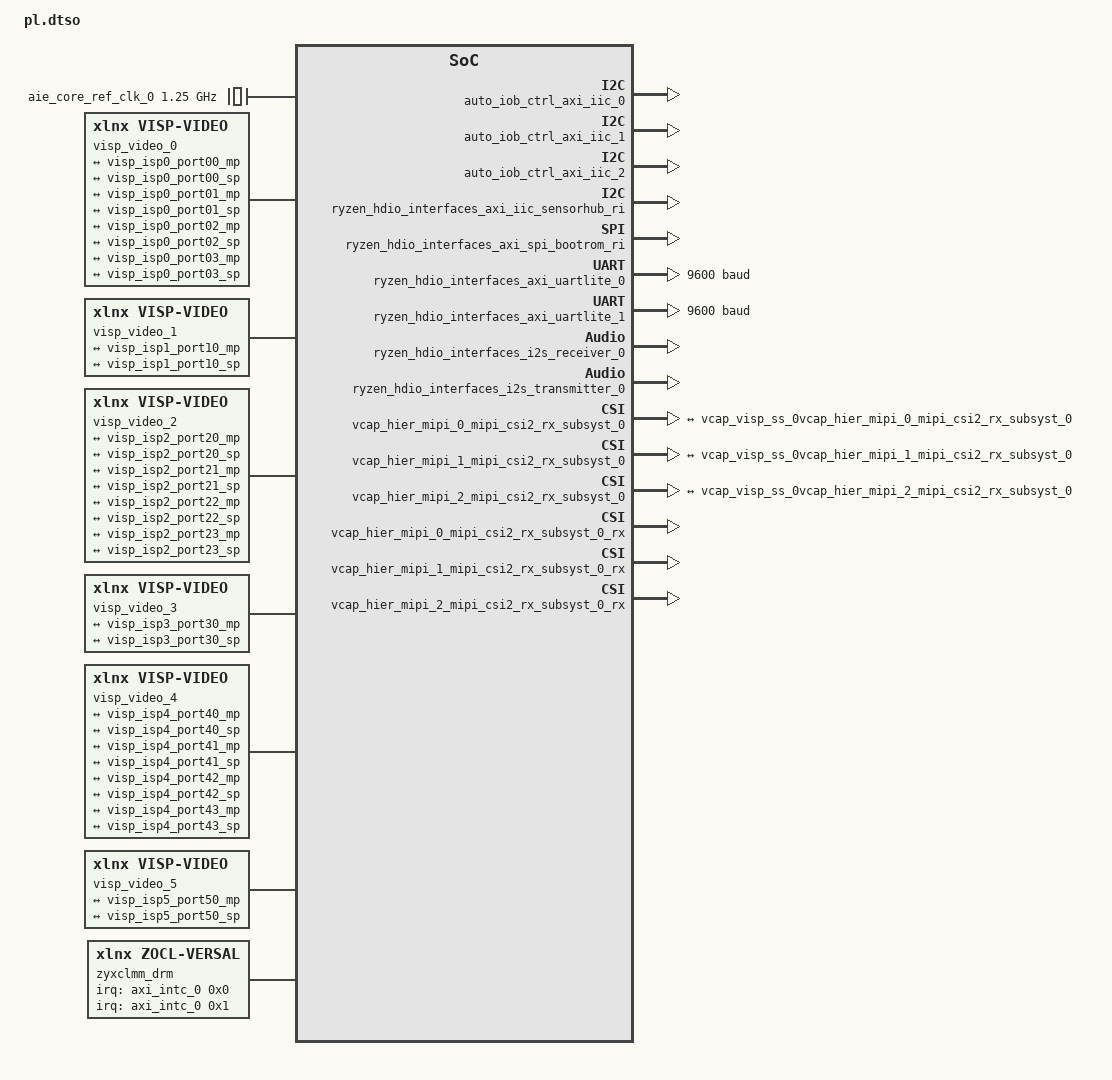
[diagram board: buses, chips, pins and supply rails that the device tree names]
/dts-v1/;
/plugin/;

&fpga {
        firmware-name = "vpl_gen_fixed_pld.pdi";

        misc_clk_2: misc_clk_2 {
                #clock-cells = <0x0>;
                clock-frequency = <0x8f0cba9>;
                compatible = "fixed-clock";
        };

        misc_clk_3: misc_clk_3 {
                #clock-cells = <0x0>;
                clock-frequency = <0x5f5e100>;
                compatible = "fixed-clock";
        };

        misc_clk_1: misc_clk_1 {
                #clock-cells = <0x0>;
                clock-frequency = <0xbebba30>;
                compatible = "fixed-clock";
        };

        misc_clk_5: misc_clk_5 {
                #clock-cells = <0x0>;
                clock-frequency = <0x7735940>;
                compatible = "fixed-clock";
        };

        misc_clk_0: misc_clk_0 {
                #clock-cells = <0x0>;
                clock-frequency = <0x5f5dd18>;
                compatible = "fixed-clock";
        };

        misc_clk_4: misc_clk_4 {
                #clock-cells = <0x0>;
                clock-frequency = <0x7f27c21>;
                compatible = "fixed-clock";
        };
};

&amba {

        axi_intc_0: interrupt-controller@b01b0000 {
                xlnx,name = "axi_intc_0";
                xlnx,async-intr = <0xffcfffff>;
                interrupt-names = "irq";
                interrupt-controller;
                xlnx,ivar-rst-val = <0x10>;
                xlnx,has-fast = <0x0>;
                clock-names = "s_axi_aclk";
                xlnx,is-fast = <0x0>;
                xlnx,processor-clk-freq-mhz = <0x64>;
                xlnx,cascade-master = <0x0>;
                xlnx,sense-of-irq-level-type = "Active_High";
                xlnx,intc-type = <0x0>;
                xlnx,has-ipr = <0x1>;
                xlnx,mb-clk-not-connected = <0x1>;
                xlnx,edk-iptype = "PERIPHERAL";
                xlnx,num-sync-ff = <0x2>;
                xlnx,has-cie = <0x1>;
                xlnx,enable-async = <0x0>;
                xlnx,has-sie = <0x1>;
                xlnx,num-intr-inputs = <0x20>;
                xlnx,irq-connection = <0x1>;
                xlnx,num-sw-intr = <0x0>;
                xlnx,s-axi-aclk-freq-mhz = <0x5f5dd18>;
                clocks = <&misc_clk_0>;
                xlnx,addr-width = <0x20>;
                reg = <0x0 0xb01b0000 0x0 0x10000>;
                xlnx,has-ilr = <0x0>;
                xlnx,ip-name = "axi_intc";
                xlnx,en-cascade-mode = <0x0>;
                interrupt-parent = <&gic>;
                xlnx,irq-active = <0x1>;
                xlnx,ivar-reset-value = <0x10>;
                xlnx,kind-of-lvl = <0xffffffff>;
                xlnx,disable-synchronizers = <0x0>;
                compatible = "xlnx,axi-intc-4.1", "xlnx,xps-intc-1.00.a";
                xlnx,has-ivr = <0x1>;
                xlnx,irq-is-level = <0x1>;
                xlnx,kind-of-edge = <0xffffffff>;
                xlnx,kind-of-intr = <0xffe38>;
                xlnx,edk-special = "INTR_CTRL";
                xlnx,sense-of-irq-edge-type = "Rising";
                interrupts = <0x0 0x8f 0x4>;
                #interrupt-cells = <0x2>;
        };

        ai_engine_0: ai_engine@20000000000 {
                xlnx,aie-site = "AIE2PS";
                xlnx,name = "ai_engine_0";
                xlnx,start-column = <0x0>;
                xlnx,name-si-axi = "S00_AXI";
                xlnx,shim-rows = /bits/ 8 <0x00 0x01>;
                xlnx,core-rows = /bits/ 8 <0x02 0x04>;
                xlnx,num-trig-out = <0x0>;
                xlnx,en-ext-rst = <0x1>;
                xlnx,num-trig-in = <0x0>;
                power-domains = <&versal2_firmware 0x18800000>;
                clock-names = "aclk0";
                xlnx,selected-nsu = <0x0>;
                xlnx,edk-iptype = "PERIPHERAL";
                xlnx,fast-dm-write;
                xlnx,clk-names = "aclk0";
                xlnx,aie-core-ref-ctrl-freqmhz = <0x4e2>;
                xlnx,num-column = <0x1>;
                xlnx,name-mi-axi = "M00_AXI";
                xlnx,num-si-axis = <0x0>;
                #address-cells = <0x2>;
                xlnx,partition-enabled = <0x0>;
                xlnx,num-clks = <0x0>;
                ranges;
                xlnx,num-noc-axis-clks = <0x0>;
                clocks = <&aie_core_ref_clk_0>;
                reg = <0x200 0x0 0x1 0x0>;
                xlnx,fast-pm-write;
                xlnx,num-si-axi = <0x1>;
                #size-cells = <0x2>;
                xlnx,ip-name = "ai_engine";
                xlnx,mi-destid-pins;
                xlnx,mem-rows = /bits/ 8 <0x01 0x01>;
                xlnx,aie-gen = [05];
                xlnx,en-addr-virtualization = <0x0>;
                xlnx,aie-max-freq = <0x4e2>;
                xlnx,num-mi-axis = <0x0>;
                xlnx,aie-ref-clk-freqmhz = <0x1fc9f08>;
                compatible = "xlnx,ai-engine-2.0", "xlnx,ai-engine-v2.0";
                xlnx,num-mi-axi = <0x18>;

                aie_aperture_0: aie_aperture@20000000000 {
                        xlnx,columns = <0x0 0x18>;
                        reg = <0x200 0x0 0x1 0x0>;
                        interrupt-names = "interrupt1", "interrupt2", "interrupt3";
                        #size-cells = <0x2>;
                        xlnx,node-id = <0x18800000>;
                        power-domains = <&versal2_firmware 0x18800000>;
                        #address-cells = <0x2>;
                        interrupts = <0x0 0xce 0x4 0x0 0xcf 0x4 0x0 0xd0 0x4>;
                        interrupt-parent = <&gic>;
                        xlnx,device-name = <0x0>;
                };
        };

        auto_iob_ctrl_axi_gpio_0: gpio@b0130000 {
                xlnx,all-inputs = <0x0>;
                xlnx,name = "auto_iob_ctrl_axi_gpio_0";
                xlnx,tri-default = <0xf00>;
                clock-names = "s_axi_aclk";
                xlnx,gpio2-width = <0x20>;
                xlnx,dout-default-2 = <0x0>;
                xlnx,edk-iptype = "PERIPHERAL";
                xlnx,gpio2-board-interface = "Custom";
                xlnx,interrupt-present = <0x0>;
                device_type = "gpio";
                gpio-controller;
                xlnx,all-outputs-2 = <0x0>;
                clocks = <&misc_clk_0>;
                xlnx,all-inputs-2 = <0x0>;
                reg = <0x0 0xb0130000 0x0 0x10000>;
                xlnx,tri-default-2 = <0xffffffff>;
                xlnx,ip-name = "axi_gpio";
                xlnx,is-dual = <0x0>;
                xlnx,dout-default = <0x24042>;
                xlnx,gpio-width = <0x18>;
                #gpio-cells = <0x2>;
                xlnx,all-outputs = <0x0>;
                compatible = "xlnx,axi-gpio-2.0", "xlnx,xps-gpio-1.00.a";
                xlnx,gpio-board-interface = "Custom";
        };

        auto_iob_ctrl_axi_gpio_1: gpio@b0140000 {
                xlnx,all-inputs = <0x0>;
                xlnx,name = "auto_iob_ctrl_axi_gpio_1";
                xlnx,tri-default = <0xffffffff>;
                clock-names = "s_axi_aclk";
                xlnx,gpio2-width = <0x20>;
                xlnx,dout-default-2 = <0x0>;
                xlnx,edk-iptype = "PERIPHERAL";
                xlnx,gpio2-board-interface = "Custom";
                xlnx,interrupt-present = <0x0>;
                device_type = "gpio";
                gpio-controller;
                xlnx,all-outputs-2 = <0x0>;
                clocks = <&misc_clk_0>;
                xlnx,all-inputs-2 = <0x0>;
                reg = <0x0 0xb0140000 0x0 0x10000>;
                xlnx,tri-default-2 = <0xffffffff>;
                xlnx,ip-name = "axi_gpio";
                xlnx,is-dual = <0x0>;
                xlnx,dout-default = <0x0>;
                xlnx,gpio-width = <0x5>;
                #gpio-cells = <0x2>;
                xlnx,all-outputs = <0x0>;
                compatible = "xlnx,axi-gpio-2.0", "xlnx,xps-gpio-1.00.a";
                xlnx,gpio-board-interface = "Custom";
        };

        auto_iob_ctrl_axi_gpio_2: gpio@b0150000 {
                xlnx,all-inputs = <0x0>;
                xlnx,name = "auto_iob_ctrl_axi_gpio_2";
                xlnx,tri-default = <0xffffffff>;
                clock-names = "s_axi_aclk";
                xlnx,gpio2-width = <0x20>;
                xlnx,dout-default-2 = <0x0>;
                xlnx,edk-iptype = "PERIPHERAL";
                xlnx,gpio2-board-interface = "Custom";
                xlnx,interrupt-present = <0x0>;
                device_type = "gpio";
                gpio-controller;
                xlnx,all-outputs-2 = <0x0>;
                clocks = <&misc_clk_0>;
                xlnx,all-inputs-2 = <0x0>;
                reg = <0x0 0xb0150000 0x0 0x10000>;
                xlnx,tri-default-2 = <0xffffffff>;
                xlnx,ip-name = "axi_gpio";
                xlnx,is-dual = <0x0>;
                xlnx,dout-default = <0x0>;
                xlnx,gpio-width = <0x5>;
                #gpio-cells = <0x2>;
                xlnx,all-outputs = <0x0>;
                compatible = "xlnx,axi-gpio-2.0", "xlnx,xps-gpio-1.00.a";
                xlnx,gpio-board-interface = "Custom";
        };

        auto_iob_ctrl_axi_gpio_3: gpio@b0160000 {
                xlnx,all-inputs = <0x0>;
                xlnx,name = "auto_iob_ctrl_axi_gpio_3";
                xlnx,tri-default = <0xffffffff>;
                clock-names = "s_axi_aclk";
                xlnx,gpio2-width = <0x20>;
                xlnx,dout-default-2 = <0x0>;
                xlnx,edk-iptype = "PERIPHERAL";
                xlnx,gpio2-board-interface = "Custom";
                xlnx,interrupt-present = <0x0>;
                device_type = "gpio";
                gpio-controller;
                xlnx,all-outputs-2 = <0x0>;
                clocks = <&misc_clk_0>;
                xlnx,all-inputs-2 = <0x0>;
                reg = <0x0 0xb0160000 0x0 0x10000>;
                xlnx,tri-default-2 = <0xffffffff>;
                xlnx,ip-name = "axi_gpio";
                xlnx,is-dual = <0x0>;
                xlnx,dout-default = <0x0>;
                xlnx,gpio-width = <0x6>;
                #gpio-cells = <0x2>;
                xlnx,all-outputs = <0x0>;
                compatible = "xlnx,axi-gpio-2.0", "xlnx,xps-gpio-1.00.a";
                xlnx,gpio-board-interface = "Custom";
        };

        auto_iob_ctrl_axi_iic_0: i2c@80000000 {
                xlnx,sda-inertial-delay = <0x0>;
                xlnx,axi-aclk-freq-mhz = <0x5f5dd18>;
                xlnx,name = "auto_iob_ctrl_axi_iic_0";
                xlnx,smbus-pmbus-host = <0x0>;
                xlnx,iic-freq = <0x186a0>;
                xlnx,timing-reg-width = <0x20>;
                xlnx,iic-board-interface = "Custom";
                interrupt-names = "iic2intc_irpt";
                xlnx,default-value = <0x0>;
                xlnx,ten-bit-adr = <0x0>;
                clock-names = "s_axi_aclk";
                xlnx,sda-level = <0x1>;
                xlnx,static-timing-reg-width = <0x0>;
                xlnx,edk-iptype = "PERIPHERAL";
                xlnx,s-axi-aclk-freq-hz = <0x5f5dd18>;
                xlnx,gpo-width = <0x1>;
                clocks = <&misc_clk_0>;
                reg = <0x0 0x80000000 0x0 0x10000>;
                xlnx,disable-setup-violation-check = <0x0>;
                xlnx,ip-name = "axi_iic";
                interrupt-parent = <&gic>;
                xlnx,scl-inertial-delay = <0x0>;
                compatible = "xlnx,axi-iic-2.1", "xlnx,xps-iic-2.00.a";
                xlnx,iic-freq-khz = <0x64>;
                interrupts = <0x0 0x5a 0x4>;
        };

        auto_iob_ctrl_axi_iic_1: i2c@80010000 {
                xlnx,sda-inertial-delay = <0x0>;
                xlnx,axi-aclk-freq-mhz = <0x5f5dd18>;
                xlnx,name = "auto_iob_ctrl_axi_iic_1";
                xlnx,smbus-pmbus-host = <0x0>;
                xlnx,iic-freq = <0x186a0>;
                xlnx,timing-reg-width = <0x20>;
                xlnx,iic-board-interface = "Custom";
                interrupt-names = "iic2intc_irpt";
                xlnx,default-value = <0x0>;
                xlnx,ten-bit-adr = <0x0>;
                clock-names = "s_axi_aclk";
                xlnx,sda-level = <0x1>;
                xlnx,static-timing-reg-width = <0x0>;
                xlnx,edk-iptype = "PERIPHERAL";
                xlnx,s-axi-aclk-freq-hz = <0x5f5dd18>;
                xlnx,gpo-width = <0x1>;
                clocks = <&misc_clk_0>;
                reg = <0x0 0x80010000 0x0 0x10000>;
                xlnx,disable-setup-violation-check = <0x0>;
                xlnx,ip-name = "axi_iic";
                interrupt-parent = <&gic>;
                xlnx,scl-inertial-delay = <0x0>;
                compatible = "xlnx,axi-iic-2.1", "xlnx,xps-iic-2.00.a";
                xlnx,iic-freq-khz = <0x64>;
                interrupts = <0x0 0x58 0x4>;
        };

        auto_iob_ctrl_axi_iic_2: i2c@80020000 {
                xlnx,sda-inertial-delay = <0x0>;
                xlnx,axi-aclk-freq-mhz = <0x5f5dd18>;
                xlnx,name = "auto_iob_ctrl_axi_iic_2";
                xlnx,smbus-pmbus-host = <0x0>;
                xlnx,iic-freq = <0x186a0>;
                xlnx,timing-reg-width = <0x20>;
                xlnx,iic-board-interface = "Custom";
                interrupt-names = "iic2intc_irpt";
                xlnx,default-value = <0x0>;
                xlnx,ten-bit-adr = <0x0>;
                clock-names = "s_axi_aclk";
                xlnx,sda-level = <0x1>;
                xlnx,static-timing-reg-width = <0x0>;
                xlnx,edk-iptype = "PERIPHERAL";
                xlnx,s-axi-aclk-freq-hz = <0x5f5dd18>;
                xlnx,gpo-width = <0x1>;
                clocks = <&misc_clk_0>;
                reg = <0x0 0x80020000 0x0 0x10000>;
                xlnx,disable-setup-violation-check = <0x0>;
                xlnx,ip-name = "axi_iic";
                interrupt-parent = <&gic>;
                xlnx,scl-inertial-delay = <0x0>;
                compatible = "xlnx,axi-iic-2.1", "xlnx,xps-iic-2.00.a";
                xlnx,iic-freq-khz = <0x64>;
                interrupts = <0x0 0x59 0x4>;
        };

        axi_gpio_rst: gpio@b01a0000 {
                xlnx,all-inputs = <0x0>;
                xlnx,name = "axi_gpio_rst";
                xlnx,tri-default = <0xffffffff>;
                clock-names = "s_axi_aclk";
                xlnx,gpio2-width = <0x20>;
                xlnx,dout-default-2 = <0x0>;
                xlnx,edk-iptype = "PERIPHERAL";
                xlnx,gpio2-board-interface = "Custom";
                xlnx,interrupt-present = <0x0>;
                device_type = "gpio";
                gpio-controller;
                xlnx,all-outputs-2 = <0x0>;
                clocks = <&misc_clk_0>;
                xlnx,all-inputs-2 = <0x0>;
                reg = <0x0 0xb01a0000 0x0 0x10000>;
                xlnx,tri-default-2 = <0xffffffff>;
                xlnx,ip-name = "axi_gpio";
                xlnx,is-dual = <0x0>;
                xlnx,dout-default = <0xffffffff>;
                xlnx,gpio-width = <0x20>;
                #gpio-cells = <0x2>;
                xlnx,all-outputs = <0x1>;
                compatible = "xlnx,axi-gpio-2.0", "xlnx,xps-gpio-1.00.a";
                xlnx,gpio-board-interface = "Custom";
        };

        messaging_axi_bram_ctrl_0: messaging_axi_bram_ctrl_0@80100000000 {
                xlnx,name = "messaging_axi_bram_ctrl_0";
                xlnx,s-axi-id-width = <0x1>;
                xlnx,mem-depth = <0x800>;
                xlnx,s-axi-ctrl-data-width = <0x20>;
                xlnx,bram-inst-mode = "EXTERNAL";
                xlnx,bram-addr-width = <0xb>;
                xlnx,data-width = <0x20>;
                clock-names = "s_axi_aclk";
                xlnx,edk-iptype = "PERIPHERAL";
                xlnx,ecc = <0x0>;
                xlnx,single-port-bram = <0x1>;
                xlnx,supports-narrow-burst = <0x0>;
                xlnx,s-axi-supports-narrow-burst = <0x0>;
                xlnx,id-width = <0x0>;
                xlnx,read-latency = <0x1>;
                xlnx,s-axi-ctrl-addr-width = <0x20>;
                clocks = <&misc_clk_0>;
                xlnx,bmg-instance = "EXTERNAL";
                reg = <0x801 0x0 0x0 0x2000>;
                xlnx,ip-name = "axi_bram_ctrl";
                xlnx,fault-inject = <0x0>;
                xlnx,use-ecc = <0x0>;
                xlnx,memory-depth = <0x800>;
                xlnx,rd-cmd-optimization = <0x0>;
                xlnx,ecc-type = <0x0>;
                xlnx,ecc-onoff-reset-value = <0x0>;
                compatible = "xlnx,axi-bram-ctrl-4.1", "xlnx,axi-bram-ctrl";
                xlnx,edk-special = "BRAM_CTRL";
                xlnx,protocol = "AXI4";
        };

        messaging_axi_bram_ctrl_1: messaging_axi_bram_ctrl_1@80100002000 {
                xlnx,name = "messaging_axi_bram_ctrl_1";
                xlnx,s-axi-id-width = <0x1>;
                xlnx,mem-depth = <0x800>;
                xlnx,s-axi-ctrl-data-width = <0x20>;
                xlnx,bram-inst-mode = "EXTERNAL";
                xlnx,bram-addr-width = <0xb>;
                xlnx,data-width = <0x20>;
                clock-names = "s_axi_aclk";
                xlnx,edk-iptype = "PERIPHERAL";
                xlnx,ecc = <0x0>;
                xlnx,single-port-bram = <0x1>;
                xlnx,supports-narrow-burst = <0x0>;
                xlnx,s-axi-supports-narrow-burst = <0x0>;
                xlnx,id-width = <0x0>;
                xlnx,read-latency = <0x1>;
                xlnx,s-axi-ctrl-addr-width = <0x20>;
                clocks = <&misc_clk_0>;
                xlnx,bmg-instance = "EXTERNAL";
                reg = <0x801 0x2000 0x0 0x2000>;
                xlnx,ip-name = "axi_bram_ctrl";
                xlnx,fault-inject = <0x0>;
                xlnx,use-ecc = <0x0>;
                xlnx,memory-depth = <0x800>;
                xlnx,rd-cmd-optimization = <0x0>;
                xlnx,ecc-type = <0x0>;
                xlnx,ecc-onoff-reset-value = <0x0>;
                compatible = "xlnx,axi-bram-ctrl-4.1", "xlnx,axi-bram-ctrl";
                xlnx,edk-special = "BRAM_CTRL";
                xlnx,protocol = "AXI4";
        };

        messaging_axi_gpio_0: gpio@80100005000 {
                xlnx,all-inputs = <0x0>;
                xlnx,name = "messaging_axi_gpio_0";
                xlnx,tri-default = <0xffffffff>;
                clock-names = "s_axi_aclk";
                xlnx,gpio2-width = <0x20>;
                xlnx,dout-default-2 = <0x0>;
                xlnx,edk-iptype = "PERIPHERAL";
                xlnx,gpio2-board-interface = "Custom";
                xlnx,interrupt-present = <0x0>;
                device_type = "gpio";
                gpio-controller;
                xlnx,all-outputs-2 = <0x0>;
                clocks = <&misc_clk_0>;
                xlnx,all-inputs-2 = <0x0>;
                reg = <0x801 0x5000 0x0 0x1000>;
                xlnx,tri-default-2 = <0xffffffff>;
                xlnx,ip-name = "axi_gpio";
                xlnx,is-dual = <0x0>;
                xlnx,dout-default = <0x0>;
                xlnx,gpio-width = <0x2>;
                #gpio-cells = <0x2>;
                xlnx,all-outputs = <0x1>;
                compatible = "xlnx,axi-gpio-2.0", "xlnx,xps-gpio-1.00.a";
                xlnx,gpio-board-interface = "Custom";
        };

        messaging_axi_gpio_1: gpio@80100004000 {
                xlnx,all-inputs = <0x0>;
                xlnx,name = "messaging_axi_gpio_1";
                xlnx,tri-default = <0xffffffff>;
                clock-names = "s_axi_aclk";
                xlnx,gpio2-width = <0x20>;
                xlnx,dout-default-2 = <0x0>;
                xlnx,edk-iptype = "PERIPHERAL";
                xlnx,gpio2-board-interface = "Custom";
                xlnx,interrupt-present = <0x0>;
                device_type = "gpio";
                gpio-controller;
                xlnx,all-outputs-2 = <0x0>;
                clocks = <&misc_clk_0>;
                xlnx,all-inputs-2 = <0x0>;
                reg = <0x801 0x4000 0x0 0x1000>;
                xlnx,tri-default-2 = <0xffffffff>;
                xlnx,ip-name = "axi_gpio";
                xlnx,is-dual = <0x0>;
                xlnx,dout-default = <0x0>;
                xlnx,gpio-width = <0x2>;
                #gpio-cells = <0x2>;
                xlnx,all-outputs = <0x1>;
                compatible = "xlnx,axi-gpio-2.0", "xlnx,xps-gpio-1.00.a";
                xlnx,gpio-board-interface = "Custom";
        };

        ryzen_hdio_interfaces_axi_gpio_0: gpio@b01c0000 {
                xlnx,all-inputs = <0x0>;
                xlnx,name = "ryzen_hdio_interfaces_axi_gpio_0";
                xlnx,tri-default = <0xffffffff>;
                clock-names = "s_axi_aclk";
                xlnx,gpio2-width = <0x20>;
                xlnx,dout-default-2 = <0x0>;
                xlnx,edk-iptype = "PERIPHERAL";
                xlnx,gpio2-board-interface = "Custom";
                xlnx,interrupt-present = <0x0>;
                device_type = "gpio";
                gpio-controller;
                xlnx,all-outputs-2 = <0x0>;
                clocks = <&misc_clk_0>;
                xlnx,all-inputs-2 = <0x0>;
                reg = <0x0 0xb01c0000 0x0 0x10000>;
                xlnx,tri-default-2 = <0xffffffff>;
                xlnx,ip-name = "axi_gpio";
                xlnx,is-dual = <0x0>;
                xlnx,dout-default = <0x0>;
                xlnx,gpio-width = <0x2>;
                #gpio-cells = <0x2>;
                xlnx,all-outputs = <0x0>;
                compatible = "xlnx,axi-gpio-2.0", "xlnx,xps-gpio-1.00.a";
                xlnx,gpio-board-interface = "Custom";
        };

        ryzen_hdio_interfaces_axi_gpio_bootrom_ri: gpio@b01d0000 {
                xlnx,all-inputs = <0x0>;
                xlnx,name = "ryzen_hdio_interfaces_axi_gpio_bootrom_ri";
                xlnx,tri-default = <0xffffffff>;
                clock-names = "s_axi_aclk";
                xlnx,gpio2-width = <0x20>;
                xlnx,dout-default-2 = <0x0>;
                xlnx,edk-iptype = "PERIPHERAL";
                xlnx,gpio2-board-interface = "Custom";
                xlnx,interrupt-present = <0x0>;
                device_type = "gpio";
                gpio-controller;
                xlnx,all-outputs-2 = <0x0>;
                clocks = <&misc_clk_0>;
                xlnx,all-inputs-2 = <0x0>;
                reg = <0x0 0xb01d0000 0x0 0x10000>;
                xlnx,tri-default-2 = <0xffffffff>;
                xlnx,ip-name = "axi_gpio";
                xlnx,is-dual = <0x0>;
                xlnx,dout-default = <0x0>;
                xlnx,gpio-width = <0x1>;
                #gpio-cells = <0x2>;
                xlnx,all-outputs = <0x0>;
                compatible = "xlnx,axi-gpio-2.0", "xlnx,xps-gpio-1.00.a";
                xlnx,gpio-board-interface = "Custom";
        };

        ryzen_hdio_interfaces_axi_gpio_sensorhub_ri: gpio@b01e0000 {
                xlnx,all-inputs = <0x0>;
                xlnx,name = "ryzen_hdio_interfaces_axi_gpio_sensorhub_ri";
                xlnx,tri-default = <0xffffffff>;
                clock-names = "s_axi_aclk";
                xlnx,gpio2-width = <0x20>;
                xlnx,dout-default-2 = <0x0>;
                xlnx,edk-iptype = "PERIPHERAL";
                xlnx,gpio2-board-interface = "Custom";
                xlnx,interrupt-present = <0x0>;
                device_type = "gpio";
                gpio-controller;
                xlnx,all-outputs-2 = <0x0>;
                clocks = <&misc_clk_0>;
                xlnx,all-inputs-2 = <0x0>;
                reg = <0x0 0xb01e0000 0x0 0x10000>;
                xlnx,tri-default-2 = <0xffffffff>;
                xlnx,ip-name = "axi_gpio";
                xlnx,is-dual = <0x0>;
                xlnx,dout-default = <0x0>;
                xlnx,gpio-width = <0x1>;
                #gpio-cells = <0x2>;
                xlnx,all-outputs = <0x0>;
                compatible = "xlnx,axi-gpio-2.0", "xlnx,xps-gpio-1.00.a";
                xlnx,gpio-board-interface = "Custom";
        };

        ryzen_hdio_interfaces_axi_iic_sensorhub_ri: i2c@b01f0000 {
                xlnx,sda-inertial-delay = <0x0>;
                xlnx,axi-aclk-freq-mhz = <0x5f5dd18>;
                xlnx,name = "ryzen_hdio_interfaces_axi_iic_sensorhub_ri";
                xlnx,smbus-pmbus-host = <0x0>;
                xlnx,iic-freq = <0x186a0>;
                xlnx,timing-reg-width = <0x20>;
                xlnx,iic-board-interface = "Custom";
                xlnx,default-value = <0x0>;
                xlnx,ten-bit-adr = <0x0>;
                clock-names = "s_axi_aclk";
                xlnx,sda-level = <0x1>;
                xlnx,static-timing-reg-width = <0x0>;
                xlnx,edk-iptype = "PERIPHERAL";
                xlnx,s-axi-aclk-freq-hz = <0x5f5dd18>;
                xlnx,gpo-width = <0x1>;
                clocks = <&misc_clk_0>;
                reg = <0x0 0xb01f0000 0x0 0x10000>;
                xlnx,disable-setup-violation-check = <0x0>;
                xlnx,ip-name = "axi_iic";
                xlnx,scl-inertial-delay = <0x0>;
                compatible = "xlnx,axi-iic-2.1", "xlnx,xps-iic-2.00.a";
                xlnx,iic-freq-khz = <0x64>;
        };

        ryzen_hdio_interfaces_axi_spi_bootrom_ri: axi_quad_spi@b0210000 {
                xlnx,name = "ryzen_hdio_interfaces_axi_spi_bootrom_ri";
                xlnx,sub-family = "versal";
                xlnx,fifo-included = <0x1>;
                xlnx,Axi4-address = <0x0>;
                xlnx,axi-interface = <0x0>;
                xlnx,spi-mem-addr-bits = <0x18>;
                xlnx,uc-family = <0x0>;
                clock-names = "ext_spi_clk", "s_axi_aclk";
                xlnx,fifo-depth = <0x10>;
                xlnx,sck-ratio1 = <0x1>;
                xlnx,spi-mode = <0x0>;
                xlnx,async-clk = <0x0>;
                xlnx,type-of-axi4-interface = <0x0>;
                xlnx,use-startup = <0x0>;
                xlnx,use-startup-int = <0x0>;
                xlnx,slaveonly = <0x0>;
                xlnx,edk-iptype = "PERIPHERAL";
                xlnx,s-axi4-data-width = <0x20>;
                xlnx,spi-memory = <0x1>;
                xlnx,num-transfer-bits = <0x8>;
                clocks = <&misc_clk_0>,
                 <&misc_clk_0>;
                bits-per-word = <0x8>;
                xlnx,new-seq-en = <0x1>;
                xlnx,dual-quad-mode = <0x0>;
                reg = <0x0 0xb0210000 0x0 0x10000>;
                xlnx,qspi-board-interface = "Custom";
                xlnx,ip-name = "axi_quad_spi";
                xlnx,shared-startup = <0x0>;
                xlnx,master-mode = <0x1>;
                xlnx,multiples16 = <0x1>;
                fifo-size = <0x10>;
                xlnx,s-axi4-id-width = <0x4>;
                xlnx,sck-ratio = <0x10>;
                xlnx,xip-perf-mode = <0x1>;
                num-cs = <0x1>;
                xlnx,byte-level-interrupt-en = <0x0>;
                xlnx,s-axi4-addr-width = <0x18>;
                xlnx,use-startup-ext = <0x0>;
                xlnx,xip-mode = <0x0>;
                xlnx,hasfifos = <0x1>;
                xlnx,num-ss-bits = <0x1>;
                xlnx,lsb-stup = <0x0>;
                compatible = "xlnx,axi-quad-spi-3.2", "xlnx,xps-spi-2.00.a";
                xlnx,select-xpm = <0x0>;
        };

        ryzen_hdio_interfaces_axi_uartlite_0: serial@b0220000 {
                xlnx,parity = "No_Parity";
                xlnx,data-bits = <0x8>;
                xlnx,name = "ryzen_hdio_interfaces_axi_uartlite_0";
                clock-names = "s_axi_aclk";
                xlnx,odd-parity = <0x0>;
                xlnx,edk-iptype = "PERIPHERAL";
                xlnx,use-parity = <0x0>;
                device_type = "serial";
                current-speed = <0x2580>;
                clocks = <&misc_clk_0>;
                xlnx,baudrate = <0x2580>;
                reg = <0x0 0xb0220000 0x0 0x10000>;
                xlnx,ip-name = "axi_uartlite";
                xlnx,s-axi-aclk-freq-hz-d = <0x5f5dd18>;
                xlnx,uartlite-board-interface = "Custom";
                port-number = <0x0>;
                compatible = "xlnx,axi-uartlite-2.0", "xlnx,xps-uartlite-1.00.a";
        };

        ryzen_hdio_interfaces_axi_uartlite_1: serial@b0230000 {
                xlnx,parity = "No_Parity";
                xlnx,data-bits = <0x8>;
                xlnx,name = "ryzen_hdio_interfaces_axi_uartlite_1";
                clock-names = "s_axi_aclk";
                xlnx,odd-parity = <0x0>;
                xlnx,edk-iptype = "PERIPHERAL";
                xlnx,use-parity = <0x0>;
                device_type = "serial";
                current-speed = <0x2580>;
                clocks = <&misc_clk_0>;
                xlnx,baudrate = <0x2580>;
                reg = <0x0 0xb0230000 0x0 0x10000>;
                xlnx,ip-name = "axi_uartlite";
                xlnx,s-axi-aclk-freq-hz-d = <0x5f5dd18>;
                xlnx,uartlite-board-interface = "Custom";
                port-number = <0x0>;
                compatible = "xlnx,axi-uartlite-2.0", "xlnx,xps-uartlite-1.00.a";
        };

        ryzen_hdio_interfaces_i2s_receiver_0: i2s_receiver@b0010000 {
                xlnx,name = "ryzen_hdio_interfaces_i2s_receiver_0";
                interrupt-names = "irq";
                xlnx,32bit-lr = <0x0>;
                clock-names = "aud_mclk", "m_axis_aud_aclk", "s_axi_ctrl_aclk";
                xlnx,is-master = <0x1>;
                xlnx,edk-iptype = "PERIPHERAL";
                xlnx,i2srx-board-interface = "Custom";
                xlnx,num-channels = <0x1>;
                clocks = <&misc_clk_0>,
                 <&misc_clk_0>,
                 <&misc_clk_0>;
                reg = <0x0 0xb0010000 0x0 0x10000>;
                xlnx,ip-name = "i2s_receiver";
                interrupt-parent = <&axi_intc_0>;
                xlnx,depth = <0x80>;
                xlnx,dwidth = <0x18>;
                compatible = "xlnx,i2s-receiver-1.0", "xlnx,i2s-receiver-1.0";
                interrupts = <0x14 0x2>;
                aud_mclk = <0x5f5dd18>;
        };

        ryzen_hdio_interfaces_i2s_transmitter_0: i2s_transmitter@b0020000 {
                xlnx,name = "ryzen_hdio_interfaces_i2s_transmitter_0";
                interrupt-names = "irq";
                xlnx,32bit-lr = <0x0>;
                clock-names = "aud_mclk", "s_axi_ctrl_aclk", "s_axis_aud_aclk";
                xlnx,i2stx-board-interface = "Custom";
                xlnx,is-master = <0x1>;
                xlnx,edk-iptype = "PERIPHERAL";
                xlnx,num-channels = <0x1>;
                clocks = <&misc_clk_0>,
                 <&misc_clk_0>,
                 <&misc_clk_0>;
                reg = <0x0 0xb0020000 0x0 0x10000>;
                xlnx,ip-name = "i2s_transmitter";
                interrupt-parent = <&axi_intc_0>;
                xlnx,depth = <0x80>;
                xlnx,dwidth = <0x18>;
                compatible = "xlnx,i2s-transmitter-1.0", "xlnx,i2s-transmitter-1.0";
                interrupts = <0x15 0x2>;
                aud_mclk = <0x5f5dd18>;
        };

        vcap_hier_mipi_0_mipi_csi2_rx_subsyst_0: mipi_csi2_rx_subsystem@b0040000 {
                xlnx,data-lane3-io-position = <0x8>;
                xlnx,dphy-mode = "SLAVE";
                xlnx,data-lane1-io-position = <0x4>;
                xlnx,csi-controller-reg-if;
                xlnx,axis-tdata-width = <0x20>;
                xlnx,csi-en-crc = <0x1>;
                xlnx,sprt-isp-bridge;
                xlnx,csi-en-activelanes;
                xlnx,dpy-line-rate = <0x5dc>;
                rxphy-present = <0x1>;
                xlnx,hs-line-rate = <0x320>;
                xlnx,inc-phy;
                xlnx,data-lane0-io-loc = "None";
                xlnx,data-lane2-io-loc-name = "None";
                xlnx,clk-lane-io-position = <0x0>;
                xlnx,csi-pxl-format = <0x2c>;
                xlnx,data-lane0-io-loc-name = "None";
                xlnx,dphy-preset = "CSI2RX_XLNX";
                xlnx,exdesboard-version = <0x2>;
                xlnx,exdes-config = "MIPI_Video_Pipe_Camera_to_Display";
                xlnx,cmn-num-lanes = <0x4>;
                xlnx,enable-shim-flop = <0x0>;
                xlnx,highaddr = <0xb0041fff>;
                csirx-connected = <&vcap_hier_mipi_0_mipi_csi2_rx_subsyst_0_rx>;
                xlnx,idly-group-name = "mipi_csi2rx_idly_group";
                xlnx,lprx-disable-extport = <0x0>;
                xlnx,hp-io-bank-selection = <0x40>;
                xlnx,yuv420-buf-dpth = <0x80>;
                csirx-present = <0x1>;
                xlnx,ooc-vid-clk = <0x65b710>;
                xlnx,data-lane0-byte = "All_Byte";
                xlnx,data-lane1-io-loc = "None";
                clock-names = "dphy_clk_200M", "lite_aclk", "video_aclk";
                xlnx,int-qor-check = <0x0>;
                xlnx,cmn-pxl-format = <0x2c>;
                xlnx,init = <0x186a0>;
                xlnx,edk-iptype = "PERIPHERAL";
                xlnx,en-csi-v2 = <0x0>;
                xlnx,axis-tdest-width = <0x4>;
                xlnx,phy-mode = "DPHY";
                xlnx,stretch-line-rate = <0x1194>;
                xlnx,data-lane3-byte = "All_Byte";
                xlnx,cmn-fifo-rd-en-cntrl;
                xlnx,is-ksb;
                xlnx,mipi-slv-int = <0x0>;
                xlnx,data-lane2-io-loc = "None";
                clocks = <&misc_clk_1>,
                 <&misc_clk_2>,
                 <&misc_clk_2>;
                xlnx,io-type = <0x0>;
                xlnx,hs-settle-ns = <0x19>;
                xlnx,clock-mask = <0x27>;
                xlnx,data-lane3-io-loc = "None";
                xlnx,dphyrx-board-interface = "Custom";
                interrupts = <0x1 0x2>;
                xlnx,csi-emb-non-img = <0x0>;
                xlnx,name = "vcap_hier_mipi_0_mipi_csi2_rx_subsyst_0";
                xlnx,en-vcx = <0x0>;
                xlnx,vc = <0x4>;
                xlnx,data-lane2-io-position = <0x6>;
                xlnx,exdes-board = "VEK280";
                xlnx,data-lane0-io-position = <0x2>;
                xlnx,mipi-rx-phy-mode = <0x1>;
                rxphy-connected = <&vcap_hier_mipi_0_mipi_csi2_rx_subsyst_0_phy>;
                xlnx,csi-filter-userdatatype;
                xlnx,cal-mode = "NONE";
                xlnx,master-riu;
                xlnx,data-lane1-byte = "All_Byte";
                xlnx,ext-mmcm = <0x0>;
                xlnx,data-lane3-io-loc-name = "None";
                xlnx,hs-timeout = <0x10005>;
                xlnx,data-lane1-io-loc-name = "None";
                interrupt-parent = <&axi_intc_0>;
                xlnx,vfb;
                xlnx,fifo-rd-en-control;
                xlnx,csi2rx-dbg = <0x0>;
                xlnx,cmn-proj-family = <0x0>;
                xlnx,cmn-num-pixels = <0x4>;
                dphy-present = <0x0>;
                xlnx,idly-tap = <0x1>;
                compatible = "xlnx,mipi-csi2-rx-subsystem-6.0", "xlnx,mipi-csi2-rx-subsystem-5.0";
                xlnx,axis-tuser-width = <0x60>;
                xlnx,cmn-inc-vfb;
                interrupt-names = "csirxss_csi_irq";
                xlnx,esc-timeout = <0x6400>;
                xlnx,clk-lane-io-loc = "None";
                xlnx,is-versal;
                xlnx,max-lanes = <0x4>;
                xlnx,clk-lane-io-loc-name = "None";
                xlnx,supportlevel = <0x1>;
                xlnx,exdes-fmc = "LI-IMX274MIPI-FMC , V1.0 , Single , Sensor";
                xlnx,csi-buf-depth = <0x1000>;
                xlnx,ppc = <0x4>;
                xlnx,vfb-tu-width = <0x1>;
                reg = <0x0 0xb0040000 0x0 0x2000>;
                xlnx,ip-name = "mipi_csi2_rx_subsystem";
                xlnx,dphy-lanes = <0x4>;
                xlnx,cmn-vc = <0x4>;
                xlnx,dpy-en-reg-if = <0x1>;
                xlnx,data-lane2-byte = "All_Byte";

                mipi_csi_portsvcap_hier_mipi_0_mipi_csi2_rx_subsyst_0: ports {
                        #size-cells = <0x0>;
                        #address-cells = <0x1>;

                        mipi_csi_port1vcap_hier_mipi_0_mipi_csi2_rx_subsyst_0: port@1 {
                                xlnx,cfa-pattern = "rggb";
                                xlnx,video-format = <0xc>;
                                reg = <0x1>;
                                xlnx,video-width = <0x8>;

                                mipi_csirx_outvcap_hier_mipi_0_mipi_csi2_rx_subsyst_0: endpoint {
                                        remote-endpoint = <&vcap_visp_ss_0vcap_hier_mipi_0_mipi_csi2_rx_subsyst_0>;
                                };
                        };

                        mipi_csi_port0vcap_hier_mipi_0_mipi_csi2_rx_subsyst_0: port@0 {
                                xlnx,cfa-pattern = "rggb";
                                xlnx,video-format = <0xc>;
                                reg = <0x0>;
                                xlnx,video-width = <0x8>;

                                mipi_csi_invcap_hier_mipi_0_mipi_csi2_rx_subsyst_0: endpoint {
                                        data-lanes = <0x1 0x2 0x3 0x4>;
                                };
                        };
                };
        };

        vcap_hier_mipi_1_mipi_csi2_rx_subsyst_0: mipi_csi2_rx_subsystem@b0060000 {
                xlnx,data-lane3-io-position = <0x8>;
                xlnx,dphy-mode = "SLAVE";
                xlnx,data-lane1-io-position = <0x4>;
                xlnx,csi-controller-reg-if;
                xlnx,axis-tdata-width = <0x20>;
                xlnx,csi-en-crc = <0x1>;
                xlnx,sprt-isp-bridge;
                xlnx,csi-en-activelanes;
                xlnx,dpy-line-rate = <0x5dc>;
                rxphy-present = <0x1>;
                xlnx,hs-line-rate = <0x320>;
                xlnx,inc-phy;
                xlnx,data-lane0-io-loc = "None";
                xlnx,data-lane2-io-loc-name = "None";
                xlnx,clk-lane-io-position = <0x0>;
                xlnx,csi-pxl-format = <0x2c>;
                xlnx,data-lane0-io-loc-name = "None";
                xlnx,dphy-preset = "CSI2RX_XLNX";
                xlnx,exdesboard-version = <0x2>;
                xlnx,exdes-config = "MIPI_Video_Pipe_Camera_to_Display";
                xlnx,cmn-num-lanes = <0x4>;
                xlnx,enable-shim-flop = <0x0>;
                xlnx,highaddr = <0xb0061fff>;
                csirx-connected = <&vcap_hier_mipi_1_mipi_csi2_rx_subsyst_0_rx>;
                xlnx,idly-group-name = "mipi_csi2rx_idly_group";
                xlnx,lprx-disable-extport = <0x0>;
                xlnx,hp-io-bank-selection = <0x40>;
                xlnx,yuv420-buf-dpth = <0x80>;
                csirx-present = <0x1>;
                xlnx,ooc-vid-clk = <0x65b710>;
                xlnx,data-lane0-byte = "All_Byte";
                xlnx,data-lane1-io-loc = "None";
                clock-names = "cnts_rxwordclkhs_in", "dphy_clk_200M", "lite_aclk", "shared_pll_clkoutphy_in", "video_aclk";
                xlnx,int-qor-check = <0x0>;
                xlnx,cmn-pxl-format = <0x2c>;
                xlnx,init = <0x186a0>;
                xlnx,edk-iptype = "PERIPHERAL";
                xlnx,en-csi-v2 = <0x0>;
                xlnx,axis-tdest-width = <0x4>;
                xlnx,phy-mode = "DPHY";
                xlnx,stretch-line-rate = <0x1194>;
                xlnx,data-lane3-byte = "All_Byte";
                xlnx,cmn-fifo-rd-en-cntrl;
                xlnx,is-ksb;
                xlnx,mipi-slv-int = <0x0>;
                xlnx,data-lane2-io-loc = "None";
                clocks = <&misc_clk_3>,
                 <&misc_clk_1>,
                 <&misc_clk_2>,
                 <&misc_clk_3>,
                 <&misc_clk_2>;
                xlnx,io-type = <0x0>;
                xlnx,hs-settle-ns = <0x19>;
                xlnx,clock-mask = <0x27>;
                xlnx,data-lane3-io-loc = "None";
                xlnx,dphyrx-board-interface = "Custom";
                interrupts = <0x2 0x2>;
                xlnx,csi-emb-non-img = <0x0>;
                xlnx,name = "vcap_hier_mipi_1_mipi_csi2_rx_subsyst_0";
                xlnx,en-vcx = <0x0>;
                xlnx,vc = <0x4>;
                xlnx,data-lane2-io-position = <0x6>;
                xlnx,exdes-board = "VEK280";
                xlnx,data-lane0-io-position = <0x2>;
                xlnx,mipi-rx-phy-mode = <0x1>;
                rxphy-connected = <&vcap_hier_mipi_1_mipi_csi2_rx_subsyst_0_phy>;
                xlnx,csi-filter-userdatatype;
                xlnx,cal-mode = "NONE";
                xlnx,master-riu;
                xlnx,data-lane1-byte = "All_Byte";
                xlnx,ext-mmcm = <0x0>;
                xlnx,data-lane3-io-loc-name = "None";
                xlnx,hs-timeout = <0x10005>;
                xlnx,data-lane1-io-loc-name = "None";
                interrupt-parent = <&axi_intc_0>;
                xlnx,vfb;
                xlnx,fifo-rd-en-control;
                xlnx,csi2rx-dbg = <0x0>;
                xlnx,cmn-proj-family = <0x0>;
                xlnx,cmn-num-pixels = <0x4>;
                dphy-present = <0x0>;
                xlnx,idly-tap = <0x1>;
                compatible = "xlnx,mipi-csi2-rx-subsystem-6.0", "xlnx,mipi-csi2-rx-subsystem-5.0";
                xlnx,axis-tuser-width = <0x60>;
                xlnx,cmn-inc-vfb;
                interrupt-names = "csirxss_csi_irq";
                xlnx,esc-timeout = <0x6400>;
                xlnx,clk-lane-io-loc = "None";
                xlnx,is-versal;
                xlnx,max-lanes = <0x4>;
                xlnx,clk-lane-io-loc-name = "None";
                xlnx,supportlevel = <0x0>;
                xlnx,exdes-fmc = "LI-IMX274MIPI-FMC , V1.0 , Single , Sensor";
                xlnx,csi-buf-depth = <0x1000>;
                xlnx,ppc = <0x4>;
                xlnx,vfb-tu-width = <0x1>;
                reg = <0x0 0xb0060000 0x0 0x2000>;
                xlnx,ip-name = "mipi_csi2_rx_subsystem";
                xlnx,dphy-lanes = <0x4>;
                xlnx,cmn-vc = <0x4>;
                xlnx,dpy-en-reg-if = <0x1>;
                xlnx,data-lane2-byte = "All_Byte";

                mipi_csi_portsvcap_hier_mipi_1_mipi_csi2_rx_subsyst_0: ports {
                        #size-cells = <0x0>;
                        #address-cells = <0x1>;

                        mipi_csi_port1vcap_hier_mipi_1_mipi_csi2_rx_subsyst_0: port@1 {
                                xlnx,cfa-pattern = "rggb";
                                xlnx,video-format = <0xc>;
                                reg = <0x1>;
                                xlnx,video-width = <0x8>;

                                mipi_csirx_outvcap_hier_mipi_1_mipi_csi2_rx_subsyst_0: endpoint {
                                        remote-endpoint = <&vcap_visp_ss_0vcap_hier_mipi_1_mipi_csi2_rx_subsyst_0>;
                                };
                        };

                        mipi_csi_port0vcap_hier_mipi_1_mipi_csi2_rx_subsyst_0: port@0 {
                                xlnx,cfa-pattern = "rggb";
                                xlnx,video-format = <0xc>;
                                reg = <0x0>;
                                xlnx,video-width = <0x8>;

                                mipi_csi_invcap_hier_mipi_1_mipi_csi2_rx_subsyst_0: endpoint {
                                        data-lanes = <0x1 0x2 0x3 0x4>;
                                };
                        };
                };
        };

        vcap_hier_mipi_2_mipi_csi2_rx_subsyst_0: mipi_csi2_rx_subsystem@b0000000 {
                xlnx,data-lane3-io-position = <0x8>;
                xlnx,dphy-mode = "SLAVE";
                xlnx,data-lane1-io-position = <0x4>;
                xlnx,csi-controller-reg-if;
                xlnx,axis-tdata-width = <0x20>;
                xlnx,csi-en-crc = <0x1>;
                xlnx,sprt-isp-bridge;
                xlnx,dpy-line-rate = <0x5dc>;
                rxphy-present = <0x1>;
                xlnx,hs-line-rate = <0x320>;
                xlnx,inc-phy;
                xlnx,data-lane0-io-loc = "None";
                xlnx,data-lane2-io-loc-name = "None";
                xlnx,clk-lane-io-position = <0x0>;
                xlnx,csi-pxl-format = <0x2c>;
                xlnx,data-lane0-io-loc-name = "None";
                xlnx,dphy-preset = "CSI2RX_XLNX";
                xlnx,exdesboard-version = <0x2>;
                xlnx,exdes-config = "MIPI_Video_Pipe_Camera_to_Display";
                xlnx,cmn-num-lanes = <0x3>;
                xlnx,enable-shim-flop = <0x0>;
                xlnx,highaddr = <0xb0001fff>;
                csirx-connected = <&vcap_hier_mipi_2_mipi_csi2_rx_subsyst_0_rx>;
                xlnx,lprx-disable-extport = <0x0>;
                xlnx,idly-group-name = "mipi_csi2rx_idly_group";
                xlnx,hp-io-bank-selection = <0x40>;
                xlnx,yuv420-buf-dpth = <0x80>;
                csirx-present = <0x1>;
                xlnx,ooc-vid-clk = <0x65b710>;
                xlnx,data-lane0-byte = "All_Byte";
                xlnx,data-lane1-io-loc = "None";
                clock-names = "dphy_clk_200M", "lite_aclk", "video_aclk";
                xlnx,int-qor-check = <0x0>;
                xlnx,cmn-pxl-format = <0x2c>;
                xlnx,init = <0x186a0>;
                xlnx,edk-iptype = "PERIPHERAL";
                xlnx,en-csi-v2 = <0x0>;
                xlnx,axis-tdest-width = <0x4>;
                xlnx,phy-mode = "CPHY";
                xlnx,stretch-line-rate = <0x1194>;
                xlnx,data-lane3-byte = "All_Byte";
                xlnx,cmn-fifo-rd-en-cntrl;
                xlnx,is-ksb;
                xlnx,mipi-slv-int = <0x0>;
                xlnx,data-lane2-io-loc = "None";
                clocks = <&misc_clk_1>,
                 <&misc_clk_2>,
                 <&misc_clk_2>;
                xlnx,io-type = <0x0>;
                xlnx,hs-settle-ns = <0x10>;
                xlnx,clock-mask = <0x27>;
                xlnx,data-lane3-io-loc = "None";
                xlnx,dphyrx-board-interface = "Custom";
                interrupts = <0x0 0x2>;
                xlnx,csi-emb-non-img = <0x0>;
                xlnx,name = "vcap_hier_mipi_2_mipi_csi2_rx_subsyst_0";
                xlnx,en-vcx = <0x0>;
                xlnx,vc = <0x4>;
                xlnx,data-lane2-io-position = <0x6>;
                xlnx,exdes-board = "VEK280";
                xlnx,data-lane0-io-position = <0x2>;
                xlnx,mipi-rx-phy-mode = <0x0>;
                rxphy-connected = <&vcap_hier_mipi_2_mipi_csi2_rx_subsyst_0_phy>;
                xlnx,csi-filter-userdatatype;
                xlnx,cal-mode = "NONE";
                xlnx,master-riu;
                xlnx,data-lane1-byte = "All_Byte";
                xlnx,ext-mmcm = <0x0>;
                xlnx,data-lane3-io-loc-name = "None";
                xlnx,hs-timeout = <0x10005>;
                xlnx,data-lane1-io-loc-name = "None";
                interrupt-parent = <&axi_intc_0>;
                xlnx,vfb;
                xlnx,fifo-rd-en-control;
                xlnx,csi2rx-dbg = <0x0>;
                xlnx,cmn-proj-family = <0x0>;
                xlnx,cmn-num-pixels = <0x4>;
                dphy-present = <0x0>;
                xlnx,idly-tap = <0x1>;
                compatible = "xlnx,mipi-csi2-rx-subsystem-6.0", "xlnx,mipi-csi2-rx-subsystem-5.0";
                xlnx,axis-tuser-width = <0x60>;
                xlnx,cmn-inc-vfb;
                interrupt-names = "csirxss_csi_irq";
                xlnx,esc-timeout = <0x6400>;
                xlnx,clk-lane-io-loc = "None";
                xlnx,is-versal;
                xlnx,max-lanes = <0x3>;
                xlnx,clk-lane-io-loc-name = "None";
                xlnx,supportlevel = <0x1>;
                xlnx,exdes-fmc = "LI-IMX274MIPI-FMC , V1.0 , Single , Sensor";
                xlnx,csi-buf-depth = <0x1000>;
                xlnx,ppc = <0x4>;
                xlnx,vfb-tu-width = <0x1>;
                reg = <0x0 0xb0000000 0x0 0x2000>;
                xlnx,ip-name = "mipi_csi2_rx_subsystem";
                xlnx,dphy-lanes = <0x3>;
                xlnx,cmn-vc = <0x4>;
                xlnx,dpy-en-reg-if = <0x1>;
                xlnx,data-lane2-byte = "All_Byte";

                mipi_csi_portsvcap_hier_mipi_2_mipi_csi2_rx_subsyst_0: ports {
                        #size-cells = <0x0>;
                        #address-cells = <0x1>;

                        mipi_csi_port1vcap_hier_mipi_2_mipi_csi2_rx_subsyst_0: port@1 {
                                xlnx,cfa-pattern = "rggb";
                                xlnx,video-format = <0xc>;
                                reg = <0x1>;
                                xlnx,video-width = <0x8>;

                                mipi_csirx_outvcap_hier_mipi_2_mipi_csi2_rx_subsyst_0: endpoint {
                                        remote-endpoint = <&vcap_visp_ss_0vcap_hier_mipi_2_mipi_csi2_rx_subsyst_0>;
                                };
                        };

                        mipi_csi_port0vcap_hier_mipi_2_mipi_csi2_rx_subsyst_0: port@0 {
                                xlnx,cfa-pattern = "rggb";
                                xlnx,video-format = <0xc>;
                                reg = <0x0>;
                                xlnx,video-width = <0x8>;

                                mipi_csi_invcap_hier_mipi_2_mipi_csi2_rx_subsyst_0: endpoint {
                                        data-lanes = <0x1 0x2 0x3>;
                                };
                        };
                };
        };

        vcu_vcu2_0: vcu2@b0030000 {
                xlnx,c0-lc-clkfbout-fract-a = <0x5>;
                xlnx,c0-lc-clkout-divide3-a = <0x16>;
                xlnx,decoder-frame-per-second-1 = <0x3c>;
                #clock-cells = <0x1>;
                xlnx,encoder-no-of-streams = <0x1>;
                xlnx,encoder-resolution-1 = "4096X2160";
                xlnx,c1-enable-decoder-jtag;
                xlnx,decoder-no-of-streams = <0x1>;
                xlnx,overdrive;
                xlnx,actual-c1-enc-mcu-and-core-clk = <0x389f8b60>;
                xlnx,c0-lc-clkin-period-b = <0x7270e0>;
                xlnx,c1-dec-mcu-and-core-clk = <0x396>;
                xlnx,c1-hdl-decoder-en = <0x1>;
                xlnx,c0-lc-clkin-period-a = <0x7270e0>;
                xlnx,c0-lc-divclk-divide-b = <0x1>;
                xlnx,c0-lc-divclk-divide-a = <0x2>;
                xlnx,c1-enc-enable-low-latency-mode;
                xlnx,c1-en-debug-clk;
                xlnx,decoder-resolution = "4096X2160";
                xlnx,c0-enc-frame-size = <0x5>;
                xlnx,c0-dec-enable-low-latency-mode;
                xlnx,c1-enc-color-depth = <0x2>;
                xlnx,c1-lc-clkfbout-mult-b = <0x15>;
                xlnx,decoder-coding-standard = "HEVC";
                xlnx,c0-enc-color-depth = <0x2>;
                xlnx,c0-no-of-dec-streams = <0x1>;
                xlnx,c1-hdl-dec-enable-low-latency-mode = <0x0>;
                xlnx,c1-lc-clkfbout-mult-a = <0x37>;
                xlnx,encoder-color-depth-1 = <0xc>;
                xlnx,c0-hdl-dec-enable-low-latency-mode = <0x0>;
                xlnx,c0-enable-decoder;
                xlnx,decoder-color-depth-1 = <0xc>;
                xlnx,c0-lc-clkout-divide2-b = <0x3>;
                xlnx,c1-enc-video-standard = <0x0>;
                xlnx,c0-lc-clkout-divide2-a = <0x4>;
                xlnx,c1-enable-encoder-jtag;
                xlnx,c1-enc-coding-type = <0x0>;
                xlnx,c1-enc-frame-size = <0x5>;
                clock-names = "dpll_ref_clk", "s_axi_lite_clk";
                xlnx,c0-enc-coding-type = <0x0>;
                xlnx,c1-enc-mcu-and-core-clk = <0x3b6>;
                xlnx,encoder-color-depth = <0xc>;
                xlnx,encoder-coding-standard-1 = "HEVC";
                xlnx,encoder-frequency-1 = <0x3b6>;
                xlnx,nsu-only;
                xlnx,edk-iptype = "PERIPHERAL";
                xlnx,c1-dec-fps = <0x3>;
                xlnx,c1-enable-decoder;
                xlnx,decoder-coding-standard-1 = "HEVC";
                xlnx,decoder-frame-per-second = <0x3c>;
                xlnx,c0-dec-fps = <0x3>;
                clocks = <&misc_clk_4>,
                 <&misc_clk_0>;
                xlnx,decoder-color-format = <0x1bc>;
                xlnx,c1-dec-color-format = <0x3>;
                xlnx,c1-no-of-enc-streams = <0x1>;
                xlnx,encoder-no-of-streams-1 = <0x1>;
                xlnx,c0-dec-frame-size = <0x5>;
                xlnx,design-topology = <0x0>;
                xlnx,c1-enable-seperate-interrupts;
                xlnx,c1-lc-clkfbout-fract-b = <0x18>;
                xlnx,actual-c0-dec-mcu-and-core-clk = <0x36b6ce30>;
                xlnx,c1-lc-clkfbout-fract-a = <0x5>;
                xlnx,c1-lc-clkout-divide3-a = <0x16>;
                xlnx,enable-instance0-dpll;
                interrupts = <0x7 0x2 0x8 0x2 0x6 0x2>;
                xlnx,name = "vcu_vcu2_0";
                xlnx,actual-c0-axi-slave-clk = <0x9f2b120>;
                xlnx,c0-lc-clkout-divide1-b = <0x3>;
                xlnx,encoder-color-format-1 = <0x1bc>;
                xlnx,c1-dec-video-standard = <0x0>;
                xlnx,c1-dpll-ctrl = <0x1>;
                xlnx,num-of-instances = <0x0>;
                xlnx,c0-dec-color-format = <0x3>;
                xlnx,c0-enable-decoder-jtag;
                xlnx,c1-dec-frame-size = <0x5>;
                xlnx,c1-ref-clk = <0x7f27450>;
                xlnx,encoder-frame-per-second = <0x3c>;
                xlnx,c0-lc-clkfbout-mult-b = <0x15>;
                xlnx,c0-ref-clk = <0x7f27450>;
                xlnx,target-board = <0x0>;
                xlnx,new-param-for-image = <0x0>;
                xlnx,c0-lc-clkfbout-mult-a = <0x37>;
                xlnx,c1-hdl-enable-decoder-jtag = <0x0>;
                xlnx,llp-module = <0x0>;
                xlnx,c0-hdl-enable-decoder-jtag = <0x0>;
                xlnx,encoder-color-format = <0x1bc>;
                xlnx,c0-axi-slave-clk = <0xa7>;
                xlnx,c1-enc-color-format = <0x3>;
                xlnx,c0-enc-video-standard = <0x0>;
                xlnx,c0-enc-enable-low-latency-mode;
                xlnx,c1-dec-enable-low-latency-mode;
                xlnx,encoder-coding-standard = "HEVC";
                xlnx,encoder-frequency = <0x3b6>;
                xlnx,c0-no-of-enc-streams = <0x1>;
                xlnx,c1-hdl-enc-enable-low-latency-mode = <0x0>;
                interrupt-parent = <&axi_intc_0>;
                xlnx,c0-hdl-encoder-en = <0x1>;
                xlnx,c0-hdl-enc-enable-low-latency-mode = <0x0>;
                xlnx,decoder-frequency = <0x41a>;
                xlnx,c0-enable-encoder;
                xlnx,actual-c0-enc-mcu-and-core-clk = <0x389f8b60>;
                xlnx,c0-dec-mcu-and-core-clk = <0x396>;
                xlnx,c1-dec-color-depth = <0x2>;
                xlnx,c1-enc-source-format = <0x0>;
                xlnx,c1-lc-divclk-divide-b = <0x1>;
                xlnx,encoder-frame-per-second-1 = <0x3c>;
                xlnx,c0-dec-color-depth = <0x2>;
                compatible = "xlnx,vcu2-3.0";
                xlnx,c1-lc-clkout-divide2-b = <0x3>;
                xlnx,c1-lc-divclk-divide-a = <0x2>;
                xlnx,enable-instance1 = <0x0>;
                xlnx,actual-c1-axi-slave-clk = <0x9f2b120>;
                xlnx,c1-lc-clkout-divide2-a = <0x4>;
                xlnx,c0-enc-color-format = <0x3>;
                interrupt-names = "c0_irq_dec_pintreq", "c0_irq_enc_pintreq", "c0_irq_error";
                xlnx,c0-enable-encoder-jtag;
                xlnx,c0-lc-clkout-divide0-b = <0x9>;
                xlnx,c0-en-debug-clk;
                xlnx,c0-dpll-ctrl = <0x1>;
                xlnx,c1-hdl-encoder-en = <0x1>;
                xlnx,decoder-color-format-1 = <0x1bc>;
                xlnx,c1-dec-coding-type = <0x0>;
                xlnx,c1-enable-encoder;
                xlnx,c1-enc-fps = <0x3>;
                xlnx,c1-hdl-enable-encoder-jtag = <0x0>;
                xlnx,c1-lc-clkin-period-b = <0x7270e0>;
                xlnx,decoder-resolution-1 = "4096X2160";
                xlnx,c0-hdl-enable-encoder-jtag = <0x0>;
                xlnx,c0-enc-fps = <0x3>;
                xlnx,c0-dec-coding-type = <0x0>;
                xlnx,c1-lc-clkin-period-a = <0x7270e0>;
                xlnx,decoder-color-depth = <0xc>;
                xlnx,one-instance = <0x0>;
                xlnx,actual-c1-dec-mcu-and-core-clk = <0x36b6ce30>;
                xlnx,c1-debug-clk-enable = <0x0>;
                xlnx,decoder-frequency-1 = <0x41a>;
                xlnx,enable-instance1-dpll;
                #address-cells = <0x2>;
                xlnx,c0-enable-seperate-interrupts;
                xlnx,c1-axi-slave-clk = <0xa7>;
                xlnx,encoder-resolution = "4096X2160";
                reg = <0x0 0xb0030000 0x0 0x10000 0x0 0xe8000000 0x0 0x100000>;
                #size-cells = <0x2>;
                xlnx,ip-name = "vcu2";
                xlnx,c0-dec-video-standard = <0x0>;
                xlnx,c0-enc-mcu-and-core-clk = <0x3b6>;
                xlnx,c1-no-of-dec-streams = <0x1>;
                xlnx,decoder-no-of-streams-1 = <0x1>;
                xlnx,c0-hdl-decoder-en = <0x1>;
                xlnx,c0-lc-clkfbout-fract-b = <0x18>;
                xlnx,c0-enc-source-format = <0x0>;
                xlnx,c0-debug-clk-enable = <0x0>;
        };

        vcap_hier_mipi_0_mipi_csi2_rx_subsyst_0_phy: vcap_hier_mipi_0_mipi_csi2_rx_subsyst_0_phy@1000 {
                xlnx,cts-en-phy-init = <0x0>;
                xlnx,reg-on = <0x1>;
                xlnx,cf2-alt-seq = <0x0>;
                xlnx,dbg-ports-on = <0x0>;
                xlnx,en-dynamic-line-rate = <0x0>;
                xlnx,resp-width = <0x2>;
                xlnx,back2back-sync = <0x0>;
                xlnx,en-timeout-regs = <0x0>;
                xlnx,exdes-config = "DPHY";
                xlnx,calib-en = <0x0>;
                xlnx,esc-clk-period = <0x32>;
                xlnx,hs-settle = <0x19>;
                clock-names = "core_clk", "s_axi_aclk";
                xlnx,init-cntr-2 = <0x14>;
                xlnx,en-alt-seq = <0x0>;
                xlnx,init-cntr-1 = <0x400>;
                xlnx,edk-iptype = "PERIPHERAL";
                xlnx,phy-mode = <0x1>;
                xlnx,stable-clk-period = <0xc8>;
                clocks = <&misc_clk_1>,
                 <&misc_clk_2>;
                xlnx,addr-width = <0x8>;
                xlnx,is-hierarchy;
                xlnx,clock-mask = <0x27>;
                xlnx,phy-preset = "CSI2RX_XLNX";
                xlnx,name = "vcap_hier_mipi_0_mipi_csi2_rx_subsyst_0_phy";
                xlnx,stb-width = <0x4>;
                xlnx,en-init-periodic-seq = <0x0>;
                xlnx,wakeup = <0x30d40>;
                xlnx,en-esc-mode = <0x0>;
                xlnx,ppi-v-width = <0x1>;
                xlnx,alp-pause-wake-stop = <0x4>;
                xlnx,hs-timeout = <0x10005>;
                xlnx,en-preamble-seq = <0x0>;
                xlnx,prbs-seed = <0x1>;
                compatible = "xlnx,mipi-rx-phy-1.0";
                xlnx,phy-lanes = <0x4>;
                xlnx,ddr-clk-period = <0x145708>;
                xlnx,lib-fifo = <0x1>;
                xlnx,data-width = <0x20>;
                xlnx,esc-timeout = <0x6400>;
                xlnx,alp-pause-wake-ulps = <0x32>;
                xlnx,supportlevel;
                xlnx,ppi-rxdwidth = <0x10>;
                xlnx,max-symbols = <0x10>;
                xlnx,line-rate = <0x5dc>;
                reg = <0x0 0xb0041000 0x0 0x1000>;
                xlnx,ip-name = "mipi_rx_phy";
                xlnx,en-alp = <0x0>;
                xlnx,en-csi-cnts-word-clk;
        };

        vcap_hier_mipi_0_mipi_csi2_rx_subsyst_0_rx: vcap_hier_mipi_0_mipi_csi2_rx_subsyst_0_rx@0 {
                xlnx,header-data-width = <0x20>;
                xlnx,axis-tdata-width = <0x30>;
                xlnx,sprt-isp-bridge;
                xlnx,csi-inv-shutdown = <0x1>;
                xlnx,csi-fixed-vc = <0x0>;
                xlnx,hs-line-rate = <0x5dc>;
                xlnx,csi-en-vc-support = <0x1>;
                xlnx,csi-opt3-fixedlanes = <0x0>;
                xlnx,hp-io-bank-selection = <0x2e>;
                xlnx,yuv420-buf-dpth = <0x80>;
                clock-names = "core_clk", "dl0_rxbyteclkhs", "m_axis_aclk", "s_axi_aclk", "video_aclk";
                xlnx,csi-opt2-crc = <0x0>;
                xlnx,cmn-pxl-format = "RAW12";
                xlnx,edk-iptype = "PERIPHERAL";
                xlnx,phy-mode = "DPHY";
                xlnx,axis-tdest-width = <0xb>;
                xlnx,csi-vc-off-9 = <0xa>;
                xlnx,csi-vc-off-8 = <0x9>;
                xlnx,csi-vc-off-7 = <0x8>;
                xlnx,mipi-slv-int = <0x0>;
                xlnx,axis-fifo-dcnt-width = <0xc>;
                clocks = <&misc_clk_1>,
                 <&misc_clk_3>,
                 <&misc_clk_2>,
                 <&misc_clk_2>,
                 <&misc_clk_2>;
                xlnx,csi-vc-off-6 = <0x7>;
                xlnx,axis-fifo-depth = <0x1000>;
                xlnx,is-hierarchy;
                xlnx,csi-vc-off-5 = <0x6>;
                xlnx,csi-lanes = <0x4>;
                xlnx,csi-vc-off-4 = <0x5>;
                xlnx,csi-vc-off-3 = <0x4>;
                xlnx,csi-vc-off-2 = <0x3>;
                xlnx,csi-vc-off-1 = <0x2>;
                xlnx,csi-vc-off-0 = <0x1>;
                xlnx,en-vcx;
                xlnx,name = "vcap_hier_mipi_0_mipi_csi2_rx_subsyst_0_rx";
                xlnx,ppi-mult = <0x1>;
                xlnx,csi-vc-off-14 = <0xf>;
                xlnx,csi-vc-off-13 = <0xe>;
                xlnx,csi-vc-off-12 = <0xd>;
                xlnx,csi-vc-off-11 = <0xc>;
                xlnx,emb-dw = <0x60>;
                xlnx,csi-vc-off-10 = <0xb>;
                xlnx,csi-offload-nonimage = <0x0>;
                xlnx,csi-filter-userdatatype = <0x1>;
                xlnx,ppi-sync-width = <0x0>;
                xlnx,disable-lite = <0x0>;
                xlnx,csi-opt1-regs = <0x0>;
                xlnx,csi2rx-dbg = <0x0>;
                xlnx,cmn-proj-family = <0x0>;
                xlnx,cmn-num-pixels = <0x4>;
                compatible = "xlnx,mipi-csi2-rx-ctrl-1.0";
                xlnx,axis-tuser-width = <0x70>;
                xlnx,cmn-inc-vfb;
                xlnx,ppi-sig-width = <0x1>;
                reg = <0x0 0xb0040000 0x0 0x1000>;
                xlnx,ip-name = "mipi_csi2_rx_ctrl";
        };

        vcap_hier_mipi_1_mipi_csi2_rx_subsyst_0_phy: vcap_hier_mipi_1_mipi_csi2_rx_subsyst_0_phy@1000 {
                xlnx,cts-en-phy-init = <0x0>;
                xlnx,reg-on = <0x1>;
                xlnx,cf2-alt-seq = <0x0>;
                xlnx,dbg-ports-on = <0x0>;
                xlnx,en-dynamic-line-rate = <0x0>;
                xlnx,resp-width = <0x2>;
                xlnx,back2back-sync = <0x0>;
                xlnx,en-timeout-regs = <0x0>;
                xlnx,exdes-config = "DPHY";
                xlnx,calib-en = <0x0>;
                xlnx,esc-clk-period = <0x32>;
                xlnx,hs-settle = <0x19>;
                clock-names = "cnts_rxwordclkhs_in", "core_clk", "s_axi_aclk";
                xlnx,init-cntr-2 = <0x14>;
                xlnx,en-alt-seq = <0x0>;
                xlnx,init-cntr-1 = <0x400>;
                xlnx,edk-iptype = "PERIPHERAL";
                xlnx,phy-mode = <0x1>;
                xlnx,stable-clk-period = <0xc8>;
                clocks = <&misc_clk_3>,
                 <&misc_clk_1>,
                 <&misc_clk_2>;
                xlnx,is-hierarchy;
                xlnx,addr-width = <0x8>;
                xlnx,clock-mask = <0x27>;
                xlnx,phy-preset = "CSI2RX_XLNX";
                xlnx,name = "vcap_hier_mipi_1_mipi_csi2_rx_subsyst_0_phy";
                xlnx,stb-width = <0x4>;
                xlnx,en-init-periodic-seq = <0x0>;
                xlnx,wakeup = <0x30d40>;
                xlnx,en-esc-mode = <0x0>;
                xlnx,ppi-v-width = <0x1>;
                xlnx,alp-pause-wake-stop = <0x4>;
                xlnx,hs-timeout = <0x10005>;
                xlnx,en-preamble-seq = <0x0>;
                xlnx,prbs-seed = <0x1>;
                compatible = "xlnx,mipi-rx-phy-1.0";
                xlnx,phy-lanes = <0x4>;
                xlnx,ddr-clk-period = <0x145708>;
                xlnx,lib-fifo = <0x1>;
                xlnx,data-width = <0x20>;
                xlnx,esc-timeout = <0x6400>;
                xlnx,alp-pause-wake-ulps = <0x32>;
                xlnx,ppi-rxdwidth = <0x10>;
                xlnx,max-symbols = <0x10>;
                xlnx,line-rate = <0x5dc>;
                reg = <0x0 0xb0061000 0x0 0x1000>;
                xlnx,ip-name = "mipi_rx_phy";
                xlnx,en-alp = <0x0>;
        };

        vcap_hier_mipi_1_mipi_csi2_rx_subsyst_0_rx: vcap_hier_mipi_1_mipi_csi2_rx_subsyst_0_rx@0 {
                xlnx,header-data-width = <0x20>;
                xlnx,axis-tdata-width = <0x30>;
                xlnx,sprt-isp-bridge;
                xlnx,csi-inv-shutdown = <0x1>;
                xlnx,csi-fixed-vc = <0x0>;
                xlnx,hs-line-rate = <0x5dc>;
                xlnx,csi-en-vc-support = <0x1>;
                xlnx,csi-opt3-fixedlanes = <0x0>;
                xlnx,hp-io-bank-selection = <0x2e>;
                xlnx,yuv420-buf-dpth = <0x80>;
                clock-names = "core_clk", "dl0_rxbyteclkhs", "m_axis_aclk", "s_axi_aclk", "video_aclk";
                xlnx,csi-opt2-crc = <0x0>;
                xlnx,cmn-pxl-format = "RAW12";
                xlnx,edk-iptype = "PERIPHERAL";
                xlnx,phy-mode = "DPHY";
                xlnx,axis-tdest-width = <0xb>;
                xlnx,csi-vc-off-9 = <0xa>;
                xlnx,csi-vc-off-8 = <0x9>;
                xlnx,csi-vc-off-7 = <0x8>;
                xlnx,mipi-slv-int = <0x0>;
                xlnx,axis-fifo-dcnt-width = <0xc>;
                clocks = <&misc_clk_1>,
                 <&misc_clk_5>,
                 <&misc_clk_2>,
                 <&misc_clk_2>,
                 <&misc_clk_2>;
                xlnx,csi-vc-off-6 = <0x7>;
                xlnx,axis-fifo-depth = <0x1000>;
                xlnx,is-hierarchy;
                xlnx,csi-vc-off-5 = <0x6>;
                xlnx,csi-lanes = <0x4>;
                xlnx,csi-vc-off-4 = <0x5>;
                xlnx,csi-vc-off-3 = <0x4>;
                xlnx,csi-vc-off-2 = <0x3>;
                xlnx,csi-vc-off-1 = <0x2>;
                xlnx,csi-vc-off-0 = <0x1>;
                xlnx,en-vcx;
                xlnx,name = "vcap_hier_mipi_1_mipi_csi2_rx_subsyst_0_rx";
                xlnx,ppi-mult = <0x1>;
                xlnx,csi-vc-off-14 = <0xf>;
                xlnx,csi-vc-off-13 = <0xe>;
                xlnx,csi-vc-off-12 = <0xd>;
                xlnx,csi-vc-off-11 = <0xc>;
                xlnx,emb-dw = <0x60>;
                xlnx,csi-vc-off-10 = <0xb>;
                xlnx,csi-offload-nonimage = <0x0>;
                xlnx,csi-filter-userdatatype = <0x1>;
                xlnx,ppi-sync-width = <0x0>;
                xlnx,disable-lite = <0x0>;
                xlnx,csi-opt1-regs = <0x0>;
                xlnx,csi2rx-dbg = <0x0>;
                xlnx,cmn-proj-family = <0x0>;
                xlnx,cmn-num-pixels = <0x4>;
                compatible = "xlnx,mipi-csi2-rx-ctrl-1.0";
                xlnx,axis-tuser-width = <0x70>;
                xlnx,cmn-inc-vfb;
                xlnx,ppi-sig-width = <0x1>;
                reg = <0x0 0xb0060000 0x0 0x1000>;
                xlnx,ip-name = "mipi_csi2_rx_ctrl";
        };

        vcap_hier_mipi_2_mipi_csi2_rx_subsyst_0_phy: vcap_hier_mipi_2_mipi_csi2_rx_subsyst_0_phy@1000 {
                xlnx,cts-en-phy-init = <0x0>;
                xlnx,reg-on = <0x1>;
                xlnx,cf2-alt-seq = <0x0>;
                xlnx,dbg-ports-on = <0x0>;
                xlnx,en-dynamic-line-rate = <0x0>;
                xlnx,resp-width = <0x2>;
                xlnx,back2back-sync = <0x0>;
                xlnx,en-timeout-regs = <0x0>;
                xlnx,exdes-config = "DPHY";
                xlnx,calib-en = <0x0>;
                xlnx,esc-clk-period = <0x32>;
                xlnx,hs-settle = <0x10>;
                clock-names = "core_clk", "s_axi_aclk";
                xlnx,init-cntr-2 = <0x11>;
                xlnx,en-alt-seq = <0x0>;
                xlnx,init-cntr-1 = <0x400>;
                xlnx,edk-iptype = "PERIPHERAL";
                xlnx,phy-mode = <0x0>;
                xlnx,stable-clk-period = <0xc8>;
                clocks = <&misc_clk_1>,
                 <&misc_clk_2>;
                xlnx,addr-width = <0x8>;
                xlnx,is-hierarchy;
                xlnx,clock-mask = <0x27>;
                xlnx,phy-preset = "None";
                xlnx,name = "vcap_hier_mipi_2_mipi_csi2_rx_subsyst_0_phy";
                xlnx,stb-width = <0x4>;
                xlnx,en-init-periodic-seq = <0x0>;
                xlnx,wakeup = <0x30d40>;
                xlnx,en-esc-mode = <0x0>;
                xlnx,ppi-v-width = <0x0>;
                xlnx,alp-pause-wake-stop = <0x9>;
                xlnx,hs-timeout = <0x10005>;
                xlnx,en-preamble-seq = <0x0>;
                xlnx,prbs-seed = <0x1>;
                compatible = "xlnx,mipi-rx-phy-1.0";
                xlnx,phy-lanes = <0x3>;
                xlnx,ddr-clk-period = <0x145708>;
                xlnx,lib-fifo = <0x1>;
                xlnx,data-width = <0x20>;
                xlnx,esc-timeout = <0x6400>;
                xlnx,alp-pause-wake-ulps = <0x16e36>;
                xlnx,supportlevel;
                xlnx,ppi-rxdwidth = <0x10>;
                xlnx,max-symbols = <0x10>;
                xlnx,line-rate = <0x5dc>;
                reg = <0x0 0xb0001000 0x0 0x1000>;
                xlnx,ip-name = "mipi_rx_phy";
                xlnx,en-alp = <0x0>;
                xlnx,en-csi-cnts-word-clk;
        };

        vcap_hier_mipi_2_mipi_csi2_rx_subsyst_0_rx: vcap_hier_mipi_2_mipi_csi2_rx_subsyst_0_rx@0 {
                xlnx,header-data-width = <0x30>;
                xlnx,axis-tdata-width = <0x30>;
                xlnx,sprt-isp-bridge;
                xlnx,csi-inv-shutdown = <0x1>;
                xlnx,csi-fixed-vc = <0x0>;
                xlnx,hs-line-rate = <0x5dc>;
                xlnx,csi-en-vc-support = <0x1>;
                xlnx,csi-opt3-fixedlanes = <0x1>;
                xlnx,hp-io-bank-selection = <0x2e>;
                xlnx,yuv420-buf-dpth = <0x80>;
                clock-names = "core_clk", "dl0_rxbyteclkhs", "m_axis_aclk", "s_axi_aclk", "video_aclk";
                xlnx,csi-opt2-crc = <0x0>;
                xlnx,cmn-pxl-format = "RAW12";
                xlnx,edk-iptype = "PERIPHERAL";
                xlnx,phy-mode = "CPHY";
                xlnx,axis-tdest-width = <0xb>;
                xlnx,csi-vc-off-9 = <0xa>;
                xlnx,csi-vc-off-8 = <0x9>;
                xlnx,csi-vc-off-7 = <0x8>;
                xlnx,mipi-slv-int = <0x0>;
                xlnx,axis-fifo-dcnt-width = <0xc>;
                clocks = <&misc_clk_1>,
                 <&misc_clk_3>,
                 <&misc_clk_2>,
                 <&misc_clk_2>,
                 <&misc_clk_2>;
                xlnx,csi-vc-off-6 = <0x7>;
                xlnx,axis-fifo-depth = <0x1000>;
                xlnx,is-hierarchy;
                xlnx,csi-vc-off-5 = <0x6>;
                xlnx,csi-lanes = <0x3>;
                xlnx,csi-vc-off-4 = <0x5>;
                xlnx,csi-vc-off-3 = <0x4>;
                xlnx,csi-vc-off-2 = <0x3>;
                xlnx,csi-vc-off-1 = <0x2>;
                xlnx,csi-vc-off-0 = <0x1>;
                xlnx,en-vcx;
                xlnx,name = "vcap_hier_mipi_2_mipi_csi2_rx_subsyst_0_rx";
                xlnx,ppi-mult = <0x1>;
                xlnx,csi-vc-off-14 = <0xf>;
                xlnx,csi-vc-off-13 = <0xe>;
                xlnx,csi-vc-off-12 = <0xd>;
                xlnx,csi-vc-off-11 = <0xc>;
                xlnx,emb-dw = <0x60>;
                xlnx,csi-vc-off-10 = <0xb>;
                xlnx,csi-offload-nonimage = <0x0>;
                xlnx,csi-filter-userdatatype = <0x1>;
                xlnx,ppi-sync-width = <0x0>;
                xlnx,disable-lite = <0x0>;
                xlnx,csi-opt1-regs = <0x0>;
                xlnx,csi2rx-dbg = <0x0>;
                xlnx,cmn-proj-family = <0x0>;
                xlnx,cmn-num-pixels = <0x4>;
                compatible = "xlnx,mipi-csi2-rx-ctrl-1.0";
                xlnx,axis-tuser-width = <0x80>;
                xlnx,cmn-inc-vfb;
                xlnx,ppi-sig-width = <0x0>;
                reg = <0x0 0xb0000000 0x0 0x1000>;
                xlnx,ip-name = "mipi_csi2_rx_ctrl";
        };

        vcap_visp_ss_0_visp_ip: vcap_visp_ss_0_visp_ip@0 {
                xlnx,tile0-isp1-oba1-sp-yuv422;
                xlnx,tile1-isp1-oba1-sp-bpp = <0xa>;
                xlnx,tile2-vidin1-tdata-width = <0x30>;
                xlnx,hdl-tile0-vidin1-data-format = <0xc>;
                xlnx,hdl-tile2-vidout12-ppc = <0x4>;
                xlnx,tile1-common-iba3-res-hor = <0xf00>;
                xlnx,hdl-tile2-vidin2-ppc = <0x4>;
                xlnx,hdl-tile2-vidout11-bpp = <0xa>;
                xlnx,tile1-isp0-rpu = <0x7>;
                xlnx,tile0-isp0-iba3-res-ver = <0x870>;
                xlnx,tile0-isp0-iba1-vcid = <0x1>;
                xlnx,tile2-enable;
                xlnx,hdl-tile1-vidin4-data-format = <0xc>;
                xlnx,hdl-tile2-isp-core-0-resolution-mp = <0x8>;
                xlnx,tile2-isp1-iba4-vcid = <0x0>;
                xlnx,tile2-isp1-oba1-mp-y;
                xlnx,ppc-converter-s0-isp = <0x0>;
                xlnx,tile2-isp0-oba0-sp-yuv422;
                xlnx,tile2-vidin4-tuser-width = <0x60>;
                xlnx,tile1-isp1-iba4-res-ver = <0x870>;
                xlnx,tile1-isp0-oba0-sp-rgb888;
                xlnx,tile1-isp0-iba0-res-hor = <0xf00>;
                xlnx,tile2-isp0-live-inputs = <0x4>;
                xlnx,hdl-tile0-isp-core-1-no-of-sensors = <0x1>;
                xlnx,hdl-tile2-vidout02-bpp = <0xa>;
                xlnx,tile2-dpll-clkout2-divide = <0x4>;
                xlnx,tile2-isp0-iba2-ppc = <0x4>;
                xlnx,hdl-llpath1-tdest-val = <0x0>;
                xlnx,tile0-isp0-actual-core-clk = <0x258>;
                xlnx,tile2-vidout11-tdata-width = <0x78>;
                xlnx,tile0-vidin4-tdata-width = <0x40>;
                xlnx,tile0-common-iba3-res-ver = <0x870>;
                xlnx,tile0-isp0-iba1-ppc = <0x4>;
                xlnx,hdl-tile0-isp-core-1-frame-rate = <0x3c>;
                xlnx,tile2-common-iba3-fps = <0xf>;
                xlnx,debug-tile1-clk-src-dpll;
                xlnx,hdl-tile0-enable;
                xlnx,tile0-common-iba3-fps = <0xf>;
                xlnx,tile2-isp1-io-type = <0x2>;
                xlnx,hdl-tile1-vidin1-tdata-width = <0x30>;
                xlnx,tile2-isp0-iba3-data-format = <0xc>;
                xlnx,tile2-vidout02-tdata-width = <0x78>;
                xlnx,hdl-tile2-isp0-iba0-vcid = <0x0>;
                xlnx,tile0-isp0-iba3-res-hor = <0xf00>;
                xlnx,debug-tile0-expose-allintf-allports = <0x0>;
                xlnx,hdl-tile2-vidin4-tdata-width = <0x40>;
                xlnx,tile1-dpll-clkfbout-mult = <0x10>;
                xlnx,tile2-isp1-rpu = <0x8>;
                xlnx,tile0-isp1-iba3-res-ver = <0x870>;
                xlnx,llpath1-clk = <0x96>;
                xlnx,hdl-tile1-vidin2-ppc = <0x4>;
                xlnx,tile0-isp0-live-inputs = <0x4>;
                xlnx,hdl-tile0-vidout01-ppc = <0x4>;
                xlnx,hdl-tile1-vidin4-tuser-width = <0x60>;
                xlnx,tile1-isp1-iba4-res-hor = <0xf00>;
                xlnx,tile1-isp1-iba4-data-format = <0xc>;
                xlnx,llpath1-tile = <0x3>;
                xlnx,tile1-isp1-oba1-sp-ir;
                xlnx,tile2-vidin2-tdata-width = <0x30>;
                xlnx,hdl-tile0-vidin2-data-format = <0xc>;
                xlnx,hdl-tile1-dpll-clkfbout-fract = <0x0>;
                xlnx,hdl-tile2-enable;
                xlnx,tile1-ref-clk = <0x8f0cd98>;
                xlnx,tile1-vidout01-tdata-width = <0x78>;
                xlnx,tile0-isp1-iba3-vcid = <0x0>;
                xlnx,tile1-common-iba3-data-format = <0xc>;
                xlnx,tile2-isp1-iba3-ppc = <0x4>;
                xlnx,debug-tile2-expose-scandfx-ports = <0x0>;
                xlnx,hdl-tile2-vidout01-tdata-width = <0x78>;
                xlnx,tile0-common-iba3-res-hor = <0xf00>;
                xlnx,tile2-common-iba3-vcid = <0x3>;
                xlnx,ppc-converter-s3-isp = <0x0>;
                xlnx,tile2-isp1-oba1-mp-rgb888;
                xlnx,tile0-isp0-io-type = <0x2>;
                xlnx,tile2-isp0-iba0-res-ver = <0x870>;
                xlnx,hdl-tile1-dpll-clkin-period = <0x65b9d7>;
                xlnx,tile2-isp0-iba2-fps = <0xf>;
                xlnx,debug-tile0-iba0-bypass = <0x0>;
                xlnx,debug-tile2-clk-src-dpll;
                xlnx,tile1-isp0-oba0-sp-yuv422;
                xlnx,hdl-tile0-isp-core-0-frame-rate = <0x3c>;
                xlnx,tile1-isp0-oba0-sp-ir;
                xlnx,tile0-isp0-iba1-fps = <0xf>;
                xlnx,tile2-isp1-live-inputs = <0x1>;
                xlnx,tile1-isp0-iba0-data-format = <0xc>;
                xlnx,tile0-isp0-oba0-sp-rgb888;
                xlnx,tile2-isp0-oba0-sp-y;
                xlnx,hdl-llpath0-delay = <0x29>;
                xlnx,tile1-dpll-clkout2-divide = <0x4>;
                xlnx,tile2-vidout12-tdata-width = <0x78>;
                xlnx,hdl-tile2-isp-core-1-frame-rate = <0x3c>;
                xlnx,hdl-tile0-dpll-clkfbout-mult = <0x10>;
                xlnx,tile0-isp1-iba3-res-hor = <0xf00>;
                xlnx,hdl-tile2-vidin0-data-format = <0xc>;
                xlnx,tile1-isp0-iba3-res-ver = <0x870>;
                xlnx,hdl-tile0-vidout12-bpp = <0xa>;
                xlnx,hdl-tile1-vidin2-tdata-width = <0x30>;
                xlnx,hdl-tile1-vidout01-ppc = <0x4>;
                xlnx,debug-tile0-iba2-bypass = <0x0>;
                xlnx,hdl-tile0-vidin2-ppc = <0x4>;
                xlnx,tile0-common-iba3-vcid = <0x3>;
                xlnx,llpath0-delay = <0x116>;
                xlnx,tile1-vidout11-tdata-width = <0x78>;
                xlnx,tile2-isp1-iba4-res-ver = <0x870>;
                xlnx,ip-name = "visp";
                xlnx,tile2-isp0-iba0-res-hor = <0xf00>;
                xlnx,hdl-llpath1-delay = <0x29>;
                xlnx,hdl-tile2-vidout11-tdata-width = <0x78>;
                xlnx,llpath0-iba = <0x0>;
                xlnx,tile1-vidin0-tdata-width = <0x30>;
                xlnx,tile2-isp1-actual-core-clk = <0x258>;
                xlnx,hdl-llpath1-tile = <0x3>;
                xlnx,tile0-isp1-netfps = <0x3c>;
                xlnx,tile0-isp1-live-inputs = <0x1>;
                xlnx,tile2-isp0-iba0-vcid = <0x0>;
                xlnx,hdl-tile0-isp-core-0-no-of-sensors = <0x4>;
                xlnx,tile1-isp0-io-type = <0x2>;
                xlnx,tile2-isp1-iba3-fps = <0x0>;
                xlnx,tile1-isp0-iba2-ppc = <0x4>;
                xlnx,hdl-llpath0-iba = <0x0>;
                xlnx,tile0-vidin0-tuser-width = <0x60>;
                xlnx,tile2-vidin3-tdata-width = <0x30>;
                xlnx,hdl-tile0-vidin3-data-format = <0xc>;
                xlnx,tile1-vidout02-tdata-width = <0x78>;
                xlnx,tile2-isp0-iba3-vcid = <0x3>;
                xlnx,tile2-isp0-oba0-mp-y;
                xlnx,hdl-tile0-dpll-clkfbout-fract = <0x0>;
                xlnx,hdl-tile1-isp-core-1-no-of-sensors = <0x1>;
                xlnx,hdl-tile2-vidout02-tdata-width = <0x78>;
                xlnx,debug-tile0-iba4-bypass = <0x0>;
                xlnx,tile2-dpll-divclk-divide = <0x1>;
                xlnx,tile2-isp1-oba1-mp-yuv422;
                xlnx,hdl-tile2-vidin0-ppc = <0x4>;
                xlnx,tile1-isp1-oba1-mp-rgb888;
                xlnx,tile0-isp0-iba2-res-ver = <0x870>;
                xlnx,debug-tile1-iba0-bypass = <0x0>;
                xlnx,llpath1-delay = <0x116>;
                xlnx,hdl-tile2-isp-core-0-frame-rate = <0x3c>;
                xlnx,tile1-isp0-iba3-res-hor = <0xf00>;
                xlnx,ppc-converter-num-streams = <0x0>;
                xlnx,hdl-tile2-vidin0-tuser-width = <0x60>;
                xlnx,tile1-isp0-iba1-data-format = <0xc>;
                xlnx,tile0-vidout01-tdata-width = <0x78>;
                xlnx,tile0-isp0-oba0-sp-yuv422;
                xlnx,tile2-isp1-core-clk = <0x23c31ef0>;
                xlnx,tile1-isp1-iba3-res-ver = <0x870>;
                xlnx,hdl-tile1-vidout12-bpp = <0xa>;
                xlnx,hdl-tile2-vidout01-ppc = <0x4>;
                xlnx,tile1-isp0-iba1-vcid = <0x1>;
                xlnx,debug-tile1-expose-scandfx-ports = <0x0>;
                xlnx,hdl-tile1-vidout01-tdata-width = <0x78>;
                xlnx,tile2-isp1-iba4-res-hor = <0xf00>;
                xlnx,tile0-isp0-rpu = <0x6>;
                xlnx,tile0-dpll-clkout2-divide = <0x4>;
                xlnx,tile2-isp0-iba0-ppc = <0x4>;
                xlnx,hdl-tile0-vidin0-tdata-width = <0x30>;
                xlnx,hdl-tile2-vidin1-data-format = <0xc>;
                xlnx,tile1-isp0-oba0-mp-bpp = <0xa>;
                xlnx,hdl-tile1-vidin3-tdata-width = <0x30>;
                xlnx,tile1-isp1-iba3-ppc = <0x4>;
                xlnx,tile0-dpll-clkin-period = <0x65b9d7>;
                xlnx,tile2-isp0-io-type = <0x2>;
                xlnx,debug-tile1-iba2-bypass = <0x0>;
                xlnx,hdl-tile0-isp1-iba4-vcid = <0x0>;
                xlnx,hdl-tile2-enabledpll;
                xlnx,llpath0-oba = <0x0>;
                xlnx,speedgrade = "-2mp";
                xlnx,hdl-tile2-dpll-clkin-period = <0x65b9d7>;
                xlnx,tile1-vidout12-tdata-width = <0x78>;
                xlnx,tile1-isp0-iba2-fps = <0xf>;
                xlnx,debug-tile1-expose-allintf-allports = <0x0>;
                xlnx,hdl-llpath0-oba = <0x0>;
                xlnx,hdl-tile1-dpll-divclk-divide = <0x1>;
                xlnx,hdl-tile2-vidout12-tdata-width = <0x78>;
                xlnx,tile0-isp0-iba2-res-hor = <0xf00>;
                xlnx,tile1-vidin1-tdata-width = <0x30>;
                xlnx,tile1-isp1-netfps = <0x3c>;
                xlnx,tile1-isp0-oba0-sp-bpp = <0xa>;
                xlnx,tile0-isp0-iba2-vcid = <0x2>;
                xlnx,tile2-vidin4-tdata-width = <0x40>;
                xlnx,hdl-tile0-vidin4-data-format = <0x10>;
                xlnx,hdl-tile1-vidin0-ppc = <0x4>;
                xlnx,tile1-isp1-iba3-res-hor = <0xf00>;
                xlnx,tile0-vidout11-tdata-width = <0x78>;
                xlnx,tile0-ref-clk = <0x8f0cd98>;
                xlnx,tile1-vidin4-tuser-width = <0x60>;
                xlnx,tile2-common-iba3-data-format = <0xc>;
                xlnx,debug-tile1-iba4-bypass = <0x0>;
                xlnx,hdl-tile2-vidin3-ppc = <0x4>;
                xlnx,hdl-tile2-vidout12-bpp = <0xa>;
                xlnx,tile0-isp1-oba1-sp-y;
                xlnx,tile2-isp0-iba3-res-ver = <0x870>;
                xlnx,hdl-tile1-vidout11-tdata-width = <0x78>;
                xlnx,tile1-isp1-mem-inputs = <0x0>;
                xlnx,tile1-isp1-actual-core-clk = <0x258>;
                xlnx,tile1-isp1-rpu = <0x7>;
                xlnx,tile1-isp1-oba1-mp-yuv422;
                xlnx,debug-tile2-iba0-bypass = <0x0>;
                xlnx,hdl-tile0-isp-core-1-resolution-mp = <0x8>;
                xlnx,tile0-isp1-oba1-mp-rgb888;
                xlnx,ppc-converter-s1-isp = <0x0>;
                xlnx,tile1-isp1-iba3-vcid = <0x0>;
                xlnx,tile1-isp0-iba2-data-format = <0xc>;
                xlnx,tile0-vidout02-tdata-width = <0x78>;
                xlnx,tile2-isp0-iba0-fps = <0xf>;
                xlnx,hdl-tile1-vidout02-tdata-width = <0x78>;
                xlnx,tile2-dpll-clkfbout-fract = <0x0>;
                xlnx,tile2-isp0-iba3-ppc = <0x4>;
                xlnx,hdl-tile1-enabledpll;
                xlnx,tile1-isp1-iba3-fps = <0x0>;
                xlnx,tile2-isp1-oba1-mp-bpp = <0xa>;
                xlnx,hdl-tile0-vidin1-tdata-width = <0x30>;
                xlnx,hdl-tile2-vidin2-data-format = <0xc>;
                xlnx,tile0-isp0-iba2-ppc = <0x4>;
                compatible = "xlnx,visp-2.0";
                xlnx,tile2-isp0-oba0-mp-rgb888;
                xlnx,tile0-isp1-iba3-data-format = <0x10>;
                xlnx,debug-tile2-apb-clk-src-axi;
                xlnx,hdl-tile1-vidin4-tdata-width = <0x30>;
                xlnx,debug-tile2-iba2-bypass = <0x0>;
                xlnx,hdl-tile1-isp-core-0-no-of-sensors = <0x4>;
                xlnx,tile0-dpll-clkfbout-mult = <0x10>;
                xlnx,debug-tile0-apb-clk-src-axi;
                xlnx,hdl-tile0-vidout11-ppc = <0x4>;
                xlnx,tile1-isp0-iba2-res-ver = <0x870>;
                xlnx,debug-tile0-expose-scandfx-ports = <0x0>;
                xlnx,hdl-tile0-vidout01-tdata-width = <0x78>;
                xlnx,hdl-tile0-vidin4-tuser-width = <0x60>;
                xlnx,tile2-isp0-iba3-res-hor = <0xf00>;
                xlnx,hdl-tile0-vidin0-ppc = <0x4>;
                xlnx,tile1-common-iba3-ppc = <0x4>;
                xlnx,tile0-config = <0x0>;
                xlnx,tile2-isp1-oba1-sp-bpp = <0xa>;
                xlnx,tile0-isp1-oba1-mp-y;
                xlnx,tile0-isp1-iba4-vcid = <0x0>;
                xlnx,tile1-vidin2-tdata-width = <0x30>;
                xlnx,tile2-isp0-oba0-ppc = <0x4>;
                xlnx,hdl-tile2-isp-core-1-no-of-sensors = <0x1>;
                xlnx,tile2-isp1-iba3-res-ver = <0x870>;
                xlnx,tile2-isp1-netfps = <0x3c>;
                xlnx,tile1-isp1-core-clk = <0x23c31ef0>;
                xlnx,hdl-tile1-vidin3-ppc = <0x4>;
                xlnx,hdl-tile0-vidout02-ppc = <0x4>;
                xlnx,tile1-isp0-mem-inputs = <0x0>;
                xlnx,hdl-tile2-dpll-clkfbout-mult = <0x10>;
                xlnx,tile1-enable;
                xlnx,hdl-tile0-vidout01-bpp = <0xa>;
                xlnx,hdl-tile0-isp0-iba0-res-hor = <0xf00>;
                xlnx,hdl-tile2-dpll-clkout-divide3 = <0x4>;
                xlnx,tile1-isp0-iba0-ppc = <0x4>;
                xlnx,tile0-vidout12-tdata-width = <0x78>;
                xlnx,tile0-isp1-oba1-mp-bpp = <0xa>;
                xlnx,hdl-tile2-dpll-clkout-divide2 = <0x4>;
                xlnx,debug-tile2-iba4-bypass = <0x0>;
                xlnx,tile2-isp1-iba4-ppc = <0x4>;
                xlnx,hdl-tile1-vidout12-tdata-width = <0x78>;
                xlnx,tile1-dpll-clkin-period = <0x65b9d7>;
                xlnx,tile0-isp1-iba3-ppc = <0x4>;
                xlnx,tile0-isp1-oba1-mp-yuv422;
                xlnx,tile2-config = <0x0>;
                xlnx,tile2-isp0-iba3-fps = <0xf>;
                xlnx,hdl-tile0-enabledpll;
                xlnx,tile0-isp0-iba1-res-ver = <0x870>;
                xlnx,tile1-isp0-iba3-data-format = <0xc>;
                xlnx,tile1-isp0-iba2-res-hor = <0xf00>;
                xlnx,tile0-isp0-iba2-fps = <0xf>;
                xlnx,hdl-tile0-isp0-iba0-vcid = <0x0>;
                xlnx,hdl-tile1-vidin0-data-format = <0xc>;
                xlnx,tile0-isp1-oba1-sp-bpp = <0xa>;
                xlnx,hdl-tile1-vidout11-ppc = <0x4>;
                xlnx,hdl-tile0-vidout11-tdata-width = <0x78>;
                xlnx,tile1-dpll-clkfbout-fract = <0x0>;
                xlnx,tile0-isp1-actual-core-clk = <0x258>;
                xlnx,tile2-vidin0-tuser-width = <0x60>;
                xlnx,hdl-tile0-vidin2-tdata-width = <0x30>;
                xlnx,hdl-tile2-vidin3-data-format = <0xc>;
                xlnx,tile2-isp0-oba0-mp-yuv422;
                xlnx,tile2-isp1-iba3-data-format = <0x10>;
                xlnx,tile2-isp1-iba3-res-hor = <0xf00>;
                xlnx,tile0-isp1-iba4-data-format = <0x10>;
                xlnx,tile2-isp1-oba1-ppc = <0x4>;
                xlnx,tile1-isp0-oba0-mp-rgb888;
                xlnx,tile1-common-iba3-fps = <0xf>;
                xlnx,hdl-tile0-isp1-iba4-res-hor = <0xf00>;
                xlnx,tile2-isp0-core-clk = <0x23c31ef0>;
                xlnx,tile2-isp0-iba1-vcid = <0x1>;
                xlnx,hdl-tile1-vidout02-ppc = <0x4>;
                xlnx,tile1-isp0-live-inputs = <0x4>;
                xlnx,tile0-vidin0-tdata-width = <0x30>;
                xlnx,tile2-dpll-clkout3-divide = <0x4>;
                xlnx,hdl-tile0-vidin3-ppc = <0x4>;
                xlnx,hdl-tile0-vidout02-tdata-width = <0x78>;
                xlnx,edk-iptype = "PERIPHERAL";
                xlnx,hdl-tile1-vidout01-bpp = <0xa>;
                xlnx,debug-tile2-expose-allintf-allports = <0x0>;
                xlnx,hdl-tile0-isp-core-0-resolution-mp = <0x8>;
                xlnx,tile1-vidin3-tdata-width = <0x30>;
                xlnx,hdl-tile1-enable;
                xlnx,tile1-isp0-iba0-fps = <0xf>;
                xlnx,llpath1-iba = <0x0>;
                xlnx,tile0-isp0-iba1-res-hor = <0xf00>;
                xlnx,hdl-tile1-isp1-iba4-vcid = <0x0>;
                xlnx,tile0-isp0-iba0-data-format = <0xc>;
                xlnx,tile2-isp1-iba4-fps = <0x3c>;
                xlnx,tile1-isp0-iba3-ppc = <0x4>;
                xlnx,tile1-dpll-divclk-divide = <0x1>;
                xlnx,tile0-isp0-oba0-sp-y;
                xlnx,hdl-llpath1-iba = <0x0>;
                xlnx,hdl-tile1-isp-core-1-resolution-mp = <0x8>;
                xlnx,hdl-tile2-vidin0-tdata-width = <0x30>;
                xlnx,hdl-llpath0-tdest-val = <0x0>;
                xlnx,tile0-isp1-iba3-fps = <0x0>;
                xlnx,tile2-isp1-oba1-sp-ir;
                xlnx,tile2-isp1-oba1-sp-rgb888;
                xlnx,hdl-tile1-isp-core-1-frame-rate = <0x3c>;
                xlnx,hdl-tile1-dpll-clkout-divide3 = <0x4>;
                xlnx,tile0-isp1-oba1-sp-ir;
                xlnx,hdl-tile1-dpll-clkout-divide2 = <0x4>;
                xlnx,hdl-tile1-vidin0-tuser-width = <0x60>;
                xlnx,hdl-tile2-vidout11-ppc = <0x4>;
                xlnx,tile1-isp0-iba2-vcid = <0x2>;
                xlnx,tile2-isp0-iba2-res-ver = <0x870>;
                xlnx,hdl-tile2-vidin1-ppc = <0x4>;
                xlnx,hdl-tile1-vidin1-data-format = <0xc>;
                xlnx,tile2-isp0-oba0-sp-ir;
                xlnx,tile1-isp0-oba0-ppc = <0x4>;
                xlnx,tile1-isp1-oba1-sp-y;
                xlnx,hdl-tile2-isp-core-0-no-of-sensors = <0x4>;
                xlnx,hdl-tile2-vidout02-ppc = <0x4>;
                xlnx,tile0-isp0-oba0-sp-ir;
                xlnx,hdl-tile0-vidout12-tdata-width = <0x78>;
                xlnx,tile0-isp1-core-clk = <0x23c31ef0>;
                xlnx,hdl-tile0-vidin3-tdata-width = <0x30>;
                xlnx,hdl-tile2-vidin4-data-format = <0x10>;
                xlnx,hdl-tile2-vidout01-bpp = <0xa>;
                xlnx,tile1-common-iba3-vcid = <0x3>;
                xlnx,tile0-isp1-rpu = <0x6>;
                xlnx,tile2-isp1-iba4-data-format = <0x10>;
                xlnx,tile0-dpll-clkfbout-fract = <0x0>;
                xlnx,tile0-isp0-iba0-vcid = <0x0>;
                xlnx,tile2-isp0-iba1-ppc = <0x4>;
                xlnx,debug-tile0-iba1-bypass = <0x0>;
                xlnx,hdl-tile1-isp0-iba0-res-hor = <0xf00>;
                xlnx,tile1-isp0-oba0-mp-yuv422;
                xlnx,tile2-isp1-iba3-vcid = <0x0>;
                xlnx,tile0-isp0-oba0-mp-rgb888;
                xlnx,tile0-isp0-iba0-ppc = <0x4>;
                xlnx,hdl-tile0-dpll-divclk-divide = <0x1>;
                xlnx,tile2-dpll-clkin-period = <0x65b9d7>;
                xlnx,tile1-isp1-live-inputs = <0x1>;
                xlnx,tile1-isp1-iba4-ppc = <0x4>;
                xlnx,tile0-vidin1-tdata-width = <0x30>;
                xlnx,tile0-isp0-oba0-mp-y;
                xlnx,tile0-isp0-iba3-vcid = <0x3>;
                xlnx,llpath1-oba = <0x0>;
                xlnx,tile1-dpll-clkout3-divide = <0x4>;
                xlnx,tile0-isp0-netfps = <0x3c>;
                xlnx,tile1-isp0-iba1-res-ver = <0x870>;
                xlnx,tile1-isp0-iba3-fps = <0xf>;
                xlnx,tile1-vidin4-tdata-width = <0x30>;
                xlnx,hdl-llpath1-oba = <0x0>;
                xlnx,tile2-isp0-iba2-res-hor = <0xf00>;
                xlnx,hdl-tile1-isp-core-0-frame-rate = <0x3c>;
                xlnx,tile2-isp0-iba0-data-format = <0xc>;
                xlnx,tile0-vidin4-tuser-width = <0x60>;
                xlnx,tile0-isp0-iba1-data-format = <0xc>;
                xlnx,tile2-isp0-actual-core-clk = <0x258>;
                xlnx,tile2-isp0-rpu = <0x8>;
                xlnx,debug-tile0-iba3-bypass = <0x0>;
                xlnx,hdl-tile2-vidin1-tdata-width = <0x30>;
                xlnx,llpath0-clk = <0x96>;
                xlnx,hdl-tile1-vidin1-ppc = <0x4>;
                xlnx,tile2-isp1-oba1-sp-yuv422;
                xlnx,tile1-isp1-iba4-vcid = <0x0>;
                xlnx,tile1-isp1-oba1-mp-y;
                xlnx,tile1-isp1-oba1-ppc = <0x4>;
                xlnx,tile1-isp1-oba1-sp-rgb888;
                xlnx,hdl-tile0-dpll-clkout-divide3 = <0x4>;
                xlnx,hdl-tile1-isp1-iba4-res-hor = <0xf00>;
                xlnx,hdl-tile2-vidin4-ppc = <0x4>;
                xlnx,tile2-dpll-clkfbout-mult = <0x10>;
                xlnx,hdl-tile0-dpll-clkout-divide2 = <0x4>;
                xlnx,tile1-isp0-core-clk = <0x23c31ef0>;
                xlnx,hdl-tile2-vidin4-tuser-width = <0x60>;
                xlnx,ppc-converter-s2-isp = <0x0>;
                xlnx,hdl-tile1-vidin2-data-format = <0xc>;
                xlnx,tile0-isp0-iba0-res-ver = <0x870>;
                xlnx,tile2-isp0-iba1-fps = <0xf>;
                xlnx,tile2-isp0-oba0-mp-bpp = <0xa>;
                xlnx,llpath0-tile = <0x3>;
                xlnx,tile1-isp0-iba1-res-hor = <0xf00>;
                xlnx,tile0-isp0-iba0-fps = <0xf>;
                xlnx,hdl-tile0-vidin4-tdata-width = <0x40>;
                xlnx,tile1-isp1-iba4-fps = <0x3c>;
                xlnx,debug-tile1-iba1-bypass = <0x0>;
                xlnx,tile0-isp0-iba3-ppc = <0x4>;
                xlnx,tile2-common-iba3-res-ver = <0x870>;
                xlnx,hdl-tile1-isp-core-0-resolution-mp = <0x8>;
                xlnx,tile0-isp0-oba0-mp-yuv422;
                xlnx,hdl-tile1-isp0-iba0-vcid = <0x0>;
                xlnx,tile0-vidin2-tdata-width = <0x30>;
                xlnx,tile2-isp0-oba0-sp-bpp = <0xa>;
                clock-names = "s_axi_lite_aclk", "tile0_pl_isp_vidin0_clk", "tile0_pl_isp_vidin1_clk", "tile0_pl_isp_vidin2_clk", "tile0_pl_isp_vidin3_clk", "tile0_pl_isp_vidin4_clk", "tile0_ref_dpll_clk", "tile1_pl_isp_vidin0_clk", "tile1_pl_isp_vidin1_clk", "tile1_pl_isp_vidin2_clk", "tile1_pl_isp_vidin3_clk", "tile1_pl_isp_vidin4_clk", "tile1_ref_dpll_clk", "tile2_pl_isp_vidin0_clk", "tile2_pl_isp_vidin1_clk", "tile2_pl_isp_vidin2_clk", "tile2_pl_isp_vidin3_clk", "tile2_pl_isp_vidin4_clk", "tile2_ref_dpll_clk";
                xlnx,hdl-tile0-vidout12-ppc = <0x4>;
                xlnx,tile1-isp0-netfps = <0x3c>;
                xlnx,hdl-tile2-isp-core-1-resolution-mp = <0x8>;
                xlnx,hdl-tile0-vidout11-bpp = <0xa>;
                xlnx,tile0-dpll-clkout3-divide = <0x4>;
                xlnx,hdl-tile0-vidin1-ppc = <0x4>;
                xlnx,hdl-tile1-dpll-clkfbout-mult = <0x10>;
                xlnx,tile2-isp0-iba1-data-format = <0xc>;
                xlnx,is-hierarchy;
                xlnx,tile0-isp0-oba0-mp-bpp = <0xa>;
                xlnx,tile0-isp0-iba2-data-format = <0xc>;
                xlnx,hdl-tile1-vidin4-ppc = <0x4>;
                xlnx,tile0-isp1-iba4-res-ver = <0x870>;
                xlnx,tile0-isp0-oba0-ppc = <0x4>;
                xlnx,debug-tile1-iba3-bypass = <0x0>;
                xlnx,hdl-tile2-vidin2-tdata-width = <0x30>;
                xlnx,tile0-isp0-iba0-res-hor = <0xf00>;
                xlnx,hdl-tile0-vidout02-bpp = <0xa>;
                xlnx,hdl-tile2-isp0-iba0-res-hor = <0xf00>;
                xlnx,tile1-isp0-iba1-ppc = <0x4>;
                xlnx,tile1-isp1-oba1-sp-yuv422;
                xlnx,name = "vcap_visp_ss_0_visp_ip";
                xlnx,tile2-ref-clk = <0x8f0cd98>;
                xlnx,tile0-isp1-oba1-sp-rgb888;
                xlnx,tile2-common-iba3-res-hor = <0xf00>;
                xlnx,tile2-vidin0-tdata-width = <0x30>;
                xlnx,hdl-tile0-vidin0-data-format = <0xc>;
                xlnx,hdl-tile2-isp1-iba4-vcid = <0x0>;
                xlnx,tile2-isp1-mem-inputs = <0x0>;
                xlnx,debug-clock-gate = <0x0>;
                xlnx,tile1-isp0-oba0-sp-y;
                xlnx,tile0-isp1-iba4-ppc = <0x4>;
                xlnx,tile0-isp0-oba0-sp-bpp = <0xa>;
                xlnx,tile0-common-iba3-data-format = <0xc>;
                xlnx,hdl-llpath0-tile = <0x3>;
                xlnx,tile1-isp0-actual-core-clk = <0x258>;
                xlnx,tile0-isp1-mem-inputs = <0x0>;
                xlnx,tile0-isp1-io-type = <0x2>;
                xlnx,tile2-isp0-iba1-res-ver = <0x870>;
                xlnx,tile1-vidin0-tuser-width = <0x60>;
                xlnx,hdl-tile1-vidin3-data-format = <0xc>;
                xlnx,tile0-isp0-iba3-fps = <0xf>;
                xlnx,tile2-isp0-oba0-sp-rgb888;
                xlnx,tile2-isp0-iba2-vcid = <0x2>;
                xlnx,hdl-tile1-vidout12-ppc = <0x4>;
                xlnx,debug-tile2-iba1-bypass = <0x0>;
                xlnx,hdl-tile1-vidout11-bpp = <0xa>;
                xlnx,tile1-common-iba3-res-ver = <0x870>;
                xlnx,tile0-isp1-iba4-res-hor = <0xf00>;
                xlnx,hdl-tile2-isp1-iba4-res-hor = <0xf00>;
                xlnx,tile0-vidin3-tdata-width = <0x30>;
                xlnx,tile0-isp1-oba1-ppc = <0x4>;
                xlnx,tile2-isp1-oba1-sp-y;
                xlnx,tile2-isp0-netfps = <0x3c>;
                xlnx,debug-tile1-apb-clk-src-axi;
                xlnx,hdl-tile0-vidin4-ppc = <0x4>;
                xlnx,hdl-tile1-vidout02-bpp = <0xa>;
                xlnx,tile1-isp0-iba0-vcid = <0x0>;
                xlnx,tile0-isp0-core-clk = <0x23c31ef0>;
                xlnx,tile0-dpll-divclk-divide = <0x1>;
                xlnx,hdl-tile1-vidin0-tdata-width = <0x30>;
                xlnx,tile1-isp1-oba1-mp-bpp = <0xa>;
                xlnx,tile1-isp0-iba0-res-ver = <0x870>;
                xlnx,tile0-enable;
                xlnx,tile2-common-iba3-ppc = <0x4>;
                xlnx,hdl-tile0-dpll-clkin-period = <0x65b9d7>;
                xlnx,tile2-isp0-iba2-data-format = <0xc>;
                xlnx,tile2-vidout01-tdata-width = <0x78>;
                xlnx,tile1-isp0-iba1-fps = <0xf>;
                xlnx,tile0-isp0-iba3-data-format = <0xc>;
                reg = <0x0 0x0 0x0 0x1000 0x0 0xe8500000 0x0 0x100000 0x0 0xe8600000 0x0 0x100000 0x0 0xe8700000 0x0 0x100000>;
                xlnx,tile0-common-iba3-ppc = <0x4>;
                xlnx,tile2-isp0-iba1-res-hor = <0xf00>;
                xlnx,tile1-isp0-oba0-mp-y;
                xlnx,tile1-isp0-iba3-vcid = <0x3>;
                xlnx,debug-tile0-clk-src-dpll;
                xlnx,debug-tile2-iba3-bypass = <0x0>;
                xlnx,hdl-tile0-vidin0-tuser-width = <0x60>;
                xlnx,hdl-tile2-vidin3-tdata-width = <0x30>;
                xlnx,tile1-isp1-io-type = <0x2>;
                xlnx,tile2-isp0-mem-inputs = <0x0>;
                xlnx,tile0-isp1-iba4-fps = <0x3c>;
                xlnx,tile0-isp0-mem-inputs = <0x0>;
                xlnx,tile1-isp1-iba3-data-format = <0x10>;
                xlnx,tile1-config = <0x0>;
                xlnx,hdl-tile2-dpll-clkfbout-fract = <0x0>;
                xlnx,hdl-tile2-dpll-divclk-divide = <0x1>;
        };

        aie_core_ref_clk_0: aie_core_ref_clk_0 {
                #clock-cells = <0x0>;
                clock-frequency = <0x4a817c80>;
                compatible = "fixed-clock";
        };

        visp_mbox_rpu_6: visp_mbox_rpu_6 {
                rpu_id = <0x6>;
                mbox-names = "tx", "rx";
                mboxes = <&ipi_5_to_ipi_3_nobuf 0x0>,
                 <&ipi_5_to_ipi_3_nobuf 0x1>;
                compatible = "xlnx,isp-mbox";
        };

        visp_mbox_rpu_7: visp_mbox_rpu_7 {
                rpu_id = <0x7>;
                mbox-names = "tx", "rx";
                mboxes = <&ipi_5_to_ipi_4_nobuf 0x0>,
                 <&ipi_5_to_ipi_4_nobuf 0x1>;
                compatible = "xlnx,isp-mbox";
        };

        visp_mbox_rpu_8: visp_mbox_rpu_8 {
                rpu_id = <0x8>;
                mbox-names = "tx", "rx";
                mboxes = <&ipi_6_to_ipi_5_nobuf 0x0>,
                 <&ipi_6_to_ipi_5_nobuf 0x1>;
                compatible = "xlnx,isp-mbox";
        };

        visp_ss_00: visp_ss@b0002000 {
                xlnx,mem_inputs = <0x0>;
                xlnx,name = "visp_ss_00";
                xlnx,iba0_vcid = <0x0>;
                xlnx,iba2_max-height = <0x870>;
                xlnx,iba3_ppc = <0x4>;
                interrupt-names = "tile0_isp0_fusa_irq", "tile0_isp0_isp_irq", "tile0_isp_isr_irq", "tile0_isp_xmpu_interrupt";
                xlnx,iba2_ppc = <0x4>;
                xlnx,rpu = <0x6>;
                xlnx,iba0_max-height = <0x870>;
                xlnx,iba1_ppc = <0x4>;
                xlnx,iba0_ppc = <0x4>;
                xlnx,iba3_vcid = <0x3>;
                xlnx,iba2_frame_rate = <0xf>;
                isp_id = <0x0>;
                xlnx,iba1_vcid = <0x1>;
                xlnx,iba3_max-height = <0x870>;
                xlnx,iba0_frame_rate = <0xf>;
                xlnx,iba3_max-width = <0xf00>;
                xlnx,netfps = <0x3c>;
                reg = <0x0 0xb0002000 0x0 0x800>;
                xlnx,iba1_max-height = <0x870>;
                xlnx,iba2_max-width = <0xf00>;
                xlnx,iba3_data_format = <0xc>;
                xlnx,ip-name = "visp_ss";
                xlnx,iba1_max-width = <0xf00>;
                xlnx,iba2_data_format = <0xc>;
                xlnx,num_streams = <0x4>;
                interrupt-parent = <&gic>;
                xlnx,iba0_max-width = <0xf00>;
                xlnx,iba1_data_format = <0xc>;
                xlnx,iba0_data_format = <0xc>;
                xlnx,io_mode = "limo";
                xlnx,iba3_frame_rate = <0xf>;
                xlnx,iba2_vcid = <0x2>;
                interrupts = <0x0 0x6a 0x4 0x0 0x6b 0x4 0x0 0x68 0x4 0x0 0x69 0x4>;
                compatible = "xlnx,visp-ss-limo-1.0";
                xlnx,iba1_frame_rate = <0xf>;

                ports00: ports {
                        #size-cells = <0x0>;
                        #address-cells = <0x1>;

                        visp_ss_000vcap_visp_ss_0: port@0 {
                                reg = <0x0>;

                                vcap_visp_ss_0vcap_hier_mipi_0_mipi_csi2_rx_subsyst_0: endpoint {
                                        remote-endpoint = <&mipi_csirx_outvcap_hier_mipi_0_mipi_csi2_rx_subsyst_0>;
                                };
                        };

                        port01: port@1 {
                                reg = <0x1>;

                                visp_isp0_port00_mp: endpoint {
                                        remote-endpoint = <&visp_video_0_0_0>;
                                        type = "output";
                                };
                        };

                        port02: port@2 {
                                reg = <0x2>;

                                visp_isp0_port00_sp: endpoint {
                                        remote-endpoint = <&visp_video_0_0_1>;
                                        type = "output";
                                };
                        };

                        visp_ss_005vcap_visp_ss_0: port@5 {
                                reg = <0x5>;
                        };

                        port06: port@6 {
                                reg = <0x6>;

                                visp_isp0_port01_mp: endpoint {
                                        remote-endpoint = <&visp_video_0_1_0>;
                                        type = "output";
                                };
                        };

                        port07: port@7 {
                                reg = <0x7>;

                                visp_isp0_port01_sp: endpoint {
                                        remote-endpoint = <&visp_video_0_1_1>;
                                        type = "output";
                                };
                        };

                        visp_ss_0010vcap_visp_ss_0: port@10 {
                                reg = <0xa>;
                        };

                        port011: port@11 {
                                reg = <0xb>;

                                visp_isp0_port02_mp: endpoint {
                                        remote-endpoint = <&visp_video_0_2_0>;
                                        type = "output";
                                };
                        };

                        port012: port@12 {
                                reg = <0xc>;

                                visp_isp0_port02_sp: endpoint {
                                        remote-endpoint = <&visp_video_0_2_1>;
                                        type = "output";
                                };
                        };

                        visp_ss_0015vcap_visp_ss_0: port@15 {
                                reg = <0xf>;
                        };

                        port016: port@16 {
                                reg = <0x10>;

                                visp_isp0_port03_mp: endpoint {
                                        remote-endpoint = <&visp_video_0_3_0>;
                                        type = "output";
                                };
                        };

                        port017: port@17 {
                                reg = <0x11>;

                                visp_isp0_port03_sp: endpoint {
                                        remote-endpoint = <&visp_video_0_3_1>;
                                        type = "output";
                                };
                        };
                };
        };

        visp_video_0: visp_video_0 {
                id = <0x0>;
                compatible = "xlnx,visp-video";

                vcap_ports00: ports {
                        #size-cells = <0x0>;
                        #address-cells = <0x1>;

                        vport01: port@0 {
                                reg = <0x0>;

                                visp_video_0_0_0: endpoint {
                                        remote-endpoint = <&visp_isp0_port00_mp>;
                                };
                        };

                        vport02: port@1 {
                                reg = <0x1>;

                                visp_video_0_0_1: endpoint {
                                        remote-endpoint = <&visp_isp0_port00_sp>;
                                };
                        };

                        vport06: port@2 {
                                reg = <0x2>;

                                visp_video_0_1_0: endpoint {
                                        remote-endpoint = <&visp_isp0_port01_mp>;
                                };
                        };

                        vport07: port@3 {
                                reg = <0x3>;

                                visp_video_0_1_1: endpoint {
                                        remote-endpoint = <&visp_isp0_port01_sp>;
                                };
                        };

                        vport011: port@4 {
                                reg = <0x4>;

                                visp_video_0_2_0: endpoint {
                                        remote-endpoint = <&visp_isp0_port02_mp>;
                                };
                        };

                        vport012: port@5 {
                                reg = <0x5>;

                                visp_video_0_2_1: endpoint {
                                        remote-endpoint = <&visp_isp0_port02_sp>;
                                };
                        };

                        vport016: port@6 {
                                reg = <0x6>;

                                visp_video_0_3_0: endpoint {
                                        remote-endpoint = <&visp_isp0_port03_mp>;
                                };
                        };

                        vport017: port@7 {
                                reg = <0x7>;

                                visp_video_0_3_1: endpoint {
                                        remote-endpoint = <&visp_isp0_port03_sp>;
                                };
                        };
                };
        };

        visp_ss_01: visp_ss@b0002800 {
                xlnx,mem_inputs = <0x0>;
                xlnx,name = "visp_ss_01";
                interrupt-names = "tile0_isp1_fusa_irq", "tile0_isp1_isp_irq";
                xlnx,rpu = <0x6>;
                xlnx,iba4_frame_rate = <0x3c>;
                isp_id = <0x1>;
                xlnx,iba4_max-width = <0xf00>;
                xlnx,iba4_data_format = <0x10>;
                xlnx,netfps = <0x3c>;
                reg = <0x0 0xb0002800 0x0 0x800>;
                xlnx,ip-name = "visp_ss";
                xlnx,num_streams = <0x1>;
                interrupt-parent = <&gic>;
                xlnx,iba4_vcid = <0x0>;
                xlnx,io_mode = "limo";
                xlnx,iba4_max-height = <0x870>;
                interrupts = <0x0 0x6c 0x4 0x0 0x6d 0x4>;
                compatible = "xlnx,visp-ss-limo-1.0";
                xlnx,iba4_ppc = <0x4>;

                ports01: ports {
                        #size-cells = <0x0>;
                        #address-cells = <0x1>;

                        visp_ss_010vcap_visp_ss_0: port@0 {
                                reg = <0x0>;
                        };

                        port11: port@1 {
                                reg = <0x1>;

                                visp_isp1_port10_mp: endpoint {
                                        remote-endpoint = <&visp_video_1_0_0>;
                                        type = "output";
                                };
                        };

                        port12: port@2 {
                                reg = <0x2>;

                                visp_isp1_port10_sp: endpoint {
                                        remote-endpoint = <&visp_video_1_0_1>;
                                        type = "output";
                                };
                        };
                };
        };

        visp_video_1: visp_video_1 {
                id = <0x1>;
                compatible = "xlnx,visp-video";

                vcap_ports01: ports {
                        #size-cells = <0x0>;
                        #address-cells = <0x1>;

                        vport11: port@0 {
                                reg = <0x0>;

                                visp_video_1_0_0: endpoint {
                                        remote-endpoint = <&visp_isp1_port10_mp>;
                                };
                        };

                        vport12: port@1 {
                                reg = <0x1>;

                                visp_video_1_0_1: endpoint {
                                        remote-endpoint = <&visp_isp1_port10_sp>;
                                };
                        };
                };
        };

        visp_ss_12: visp_ss@b0003000 {
                xlnx,mem_inputs = <0x0>;
                xlnx,name = "visp_ss_12";
                xlnx,iba0_vcid = <0x0>;
                xlnx,iba2_max-height = <0x870>;
                xlnx,iba3_ppc = <0x4>;
                interrupt-names = "tile1_isp0_fusa_irq", "tile1_isp0_isp_irq", "tile1_isp_isr_irq", "tile1_isp_xmpu_interrupt";
                xlnx,iba2_ppc = <0x4>;
                xlnx,rpu = <0x7>;
                xlnx,iba0_max-height = <0x870>;
                xlnx,iba1_ppc = <0x4>;
                xlnx,iba0_ppc = <0x4>;
                xlnx,iba3_vcid = <0x3>;
                xlnx,iba2_frame_rate = <0xf>;
                isp_id = <0x2>;
                xlnx,iba1_vcid = <0x1>;
                xlnx,iba3_max-height = <0x870>;
                xlnx,iba0_frame_rate = <0xf>;
                xlnx,iba3_max-width = <0xf00>;
                xlnx,netfps = <0x3c>;
                reg = <0x0 0xb0003000 0x0 0x800>;
                xlnx,iba1_max-height = <0x870>;
                xlnx,iba2_max-width = <0xf00>;
                xlnx,iba3_data_format = <0xc>;
                xlnx,ip-name = "visp_ss";
                xlnx,iba1_max-width = <0xf00>;
                xlnx,iba2_data_format = <0xc>;
                xlnx,num_streams = <0x4>;
                interrupt-parent = <&gic>;
                xlnx,iba0_max-width = <0xf00>;
                xlnx,iba1_data_format = <0xc>;
                xlnx,iba0_data_format = <0xc>;
                xlnx,io_mode = "limo";
                xlnx,iba3_frame_rate = <0xf>;
                xlnx,iba2_vcid = <0x2>;
                interrupts = <0x0 0x33 0x4 0x0 0x34 0x4 0x0 0x6e 0x4 0x0 0x6f 0x4>;
                compatible = "xlnx,visp-ss-limo-1.0";
                xlnx,iba1_frame_rate = <0xf>;

                ports12: ports {
                        #size-cells = <0x0>;
                        #address-cells = <0x1>;

                        visp_ss_120vcap_visp_ss_0: port@0 {
                                reg = <0x0>;

                                vcap_visp_ss_0vcap_hier_mipi_1_mipi_csi2_rx_subsyst_0: endpoint {
                                        remote-endpoint = <&mipi_csirx_outvcap_hier_mipi_1_mipi_csi2_rx_subsyst_0>;
                                };
                        };

                        port21: port@1 {
                                reg = <0x1>;

                                visp_isp2_port20_mp: endpoint {
                                        remote-endpoint = <&visp_video_2_0_0>;
                                        type = "output";
                                };
                        };

                        port22: port@2 {
                                reg = <0x2>;

                                visp_isp2_port20_sp: endpoint {
                                        remote-endpoint = <&visp_video_2_0_1>;
                                        type = "output";
                                };
                        };

                        visp_ss_125vcap_visp_ss_0: port@5 {
                                reg = <0x5>;
                        };

                        port26: port@6 {
                                reg = <0x6>;

                                visp_isp2_port21_mp: endpoint {
                                        remote-endpoint = <&visp_video_2_1_0>;
                                        type = "output";
                                };
                        };

                        port27: port@7 {
                                reg = <0x7>;

                                visp_isp2_port21_sp: endpoint {
                                        remote-endpoint = <&visp_video_2_1_1>;
                                        type = "output";
                                };
                        };

                        visp_ss_1210vcap_visp_ss_0: port@10 {
                                reg = <0xa>;
                        };

                        port211: port@11 {
                                reg = <0xb>;

                                visp_isp2_port22_mp: endpoint {
                                        remote-endpoint = <&visp_video_2_2_0>;
                                        type = "output";
                                };
                        };

                        port212: port@12 {
                                reg = <0xc>;

                                visp_isp2_port22_sp: endpoint {
                                        remote-endpoint = <&visp_video_2_2_1>;
                                        type = "output";
                                };
                        };

                        visp_ss_1215vcap_visp_ss_0: port@15 {
                                reg = <0xf>;
                        };

                        port216: port@16 {
                                reg = <0x10>;

                                visp_isp2_port23_mp: endpoint {
                                        remote-endpoint = <&visp_video_2_3_0>;
                                        type = "output";
                                };
                        };

                        port217: port@17 {
                                reg = <0x11>;

                                visp_isp2_port23_sp: endpoint {
                                        remote-endpoint = <&visp_video_2_3_1>;
                                        type = "output";
                                };
                        };
                };
        };

        visp_video_2: visp_video_2 {
                id = <0x2>;
                compatible = "xlnx,visp-video";

                vcap_ports12: ports {
                        #size-cells = <0x0>;
                        #address-cells = <0x1>;

                        vport21: port@0 {
                                reg = <0x0>;

                                visp_video_2_0_0: endpoint {
                                        remote-endpoint = <&visp_isp2_port20_mp>;
                                };
                        };

                        vport22: port@1 {
                                reg = <0x1>;

                                visp_video_2_0_1: endpoint {
                                        remote-endpoint = <&visp_isp2_port20_sp>;
                                };
                        };

                        vport26: port@2 {
                                reg = <0x2>;

                                visp_video_2_1_0: endpoint {
                                        remote-endpoint = <&visp_isp2_port21_mp>;
                                };
                        };

                        vport27: port@3 {
                                reg = <0x3>;

                                visp_video_2_1_1: endpoint {
                                        remote-endpoint = <&visp_isp2_port21_sp>;
                                };
                        };

                        vport211: port@4 {
                                reg = <0x4>;

                                visp_video_2_2_0: endpoint {
                                        remote-endpoint = <&visp_isp2_port22_mp>;
                                };
                        };

                        vport212: port@5 {
                                reg = <0x5>;

                                visp_video_2_2_1: endpoint {
                                        remote-endpoint = <&visp_isp2_port22_sp>;
                                };
                        };

                        vport216: port@6 {
                                reg = <0x6>;

                                visp_video_2_3_0: endpoint {
                                        remote-endpoint = <&visp_isp2_port23_mp>;
                                };
                        };

                        vport217: port@7 {
                                reg = <0x7>;

                                visp_video_2_3_1: endpoint {
                                        remote-endpoint = <&visp_isp2_port23_sp>;
                                };
                        };
                };
        };

        visp_ss_13: visp_ss@b0003800 {
                xlnx,mem_inputs = <0x0>;
                xlnx,name = "visp_ss_13";
                interrupt-names = "tile1_isp1_fusa_irq", "tile1_isp1_isp_irq";
                xlnx,rpu = <0x7>;
                xlnx,iba4_frame_rate = <0x3c>;
                isp_id = <0x3>;
                xlnx,iba4_max-width = <0xf00>;
                xlnx,iba4_data_format = <0xc>;
                xlnx,netfps = <0x3c>;
                reg = <0x0 0xb0003800 0x0 0x800>;
                xlnx,ip-name = "visp_ss";
                xlnx,num_streams = <0x1>;
                interrupt-parent = <&gic>;
                xlnx,iba4_vcid = <0x0>;
                xlnx,io_mode = "limo";
                xlnx,iba4_max-height = <0x870>;
                interrupts = <0x0 0x35 0x4 0x0 0x36 0x4>;
                compatible = "xlnx,visp-ss-limo-1.0";
                xlnx,iba4_ppc = <0x4>;

                ports13: ports {
                        #size-cells = <0x0>;
                        #address-cells = <0x1>;

                        visp_ss_130vcap_visp_ss_0: port@0 {
                                reg = <0x0>;
                        };

                        port31: port@1 {
                                reg = <0x1>;

                                visp_isp3_port30_mp: endpoint {
                                        remote-endpoint = <&visp_video_3_0_0>;
                                        type = "output";
                                };
                        };

                        port32: port@2 {
                                reg = <0x2>;

                                visp_isp3_port30_sp: endpoint {
                                        remote-endpoint = <&visp_video_3_0_1>;
                                        type = "output";
                                };
                        };
                };
        };

        visp_video_3: visp_video_3 {
                id = <0x3>;
                compatible = "xlnx,visp-video";

                vcap_ports13: ports {
                        #size-cells = <0x0>;
                        #address-cells = <0x1>;

                        vport31: port@0 {
                                reg = <0x0>;

                                visp_video_3_0_0: endpoint {
                                        remote-endpoint = <&visp_isp3_port30_mp>;
                                };
                        };

                        vport32: port@1 {
                                reg = <0x1>;

                                visp_video_3_0_1: endpoint {
                                        remote-endpoint = <&visp_isp3_port30_sp>;
                                };
                        };
                };
        };

        visp_ss_24: visp_ss@b0004000 {
                xlnx,mem_inputs = <0x0>;
                xlnx,name = "visp_ss_24";
                xlnx,iba0_vcid = <0x0>;
                xlnx,iba2_max-height = <0x870>;
                xlnx,iba3_ppc = <0x4>;
                interrupt-names = "tile2_isp0_fusa_irq", "tile2_isp0_isp_irq", "tile2_isp_isr_irq", "tile2_isp_xmpu_interrupt";
                xlnx,iba2_ppc = <0x4>;
                xlnx,rpu = <0x8>;
                xlnx,iba0_max-height = <0x870>;
                xlnx,iba1_ppc = <0x4>;
                xlnx,iba0_ppc = <0x4>;
                xlnx,iba3_vcid = <0x3>;
                xlnx,iba2_frame_rate = <0xf>;
                isp_id = <0x4>;
                xlnx,iba1_vcid = <0x1>;
                xlnx,iba3_max-height = <0x870>;
                xlnx,iba0_frame_rate = <0xf>;
                xlnx,iba3_max-width = <0xf00>;
                xlnx,netfps = <0x3c>;
                reg = <0x0 0xb0004000 0x0 0x800>;
                xlnx,iba1_max-height = <0x870>;
                xlnx,iba2_max-width = <0xf00>;
                xlnx,iba3_data_format = <0xc>;
                xlnx,ip-name = "visp_ss";
                xlnx,iba1_max-width = <0xf00>;
                xlnx,iba2_data_format = <0xc>;
                xlnx,num_streams = <0x4>;
                interrupt-parent = <&gic>;
                xlnx,iba0_max-width = <0xf00>;
                xlnx,iba1_data_format = <0xc>;
                xlnx,iba0_data_format = <0xc>;
                xlnx,io_mode = "limo";
                xlnx,iba3_frame_rate = <0xf>;
                xlnx,iba2_vcid = <0x2>;
                interrupts = <0x0 0x54 0x4 0x0 0x55 0x4 0x0 0x52 0x4 0x0 0x53 0x4>;
                compatible = "xlnx,visp-ss-limo-1.0";
                xlnx,iba1_frame_rate = <0xf>;

                ports24: ports {
                        #size-cells = <0x0>;
                        #address-cells = <0x1>;

                        visp_ss_240vcap_visp_ss_0: port@0 {
                                reg = <0x0>;

                                vcap_visp_ss_0vcap_hier_mipi_2_mipi_csi2_rx_subsyst_0: endpoint {
                                        remote-endpoint = <&mipi_csirx_outvcap_hier_mipi_2_mipi_csi2_rx_subsyst_0>;
                                };
                        };

                        port41: port@1 {
                                reg = <0x1>;

                                visp_isp4_port40_mp: endpoint {
                                        remote-endpoint = <&visp_video_4_0_0>;
                                        type = "output";
                                };
                        };

                        port42: port@2 {
                                reg = <0x2>;

                                visp_isp4_port40_sp: endpoint {
                                        remote-endpoint = <&visp_video_4_0_1>;
                                        type = "output";
                                };
                        };

                        visp_ss_245vcap_visp_ss_0: port@5 {
                                reg = <0x5>;
                        };

                        port46: port@6 {
                                reg = <0x6>;

                                visp_isp4_port41_mp: endpoint {
                                        remote-endpoint = <&visp_video_4_1_0>;
                                        type = "output";
                                };
                        };

                        port47: port@7 {
                                reg = <0x7>;

                                visp_isp4_port41_sp: endpoint {
                                        remote-endpoint = <&visp_video_4_1_1>;
                                        type = "output";
                                };
                        };

                        visp_ss_2410vcap_visp_ss_0: port@10 {
                                reg = <0xa>;
                        };

                        port411: port@11 {
                                reg = <0xb>;

                                visp_isp4_port42_mp: endpoint {
                                        remote-endpoint = <&visp_video_4_2_0>;
                                        type = "output";
                                };
                        };

                        port412: port@12 {
                                reg = <0xc>;

                                visp_isp4_port42_sp: endpoint {
                                        remote-endpoint = <&visp_video_4_2_1>;
                                        type = "output";
                                };
                        };

                        visp_ss_2415vcap_visp_ss_0: port@15 {
                                reg = <0xf>;
                        };

                        port416: port@16 {
                                reg = <0x10>;

                                visp_isp4_port43_mp: endpoint {
                                        remote-endpoint = <&visp_video_4_3_0>;
                                        type = "output";
                                };
                        };

                        port417: port@17 {
                                reg = <0x11>;

                                visp_isp4_port43_sp: endpoint {
                                        remote-endpoint = <&visp_video_4_3_1>;
                                        type = "output";
                                };
                        };
                };
        };

        visp_video_4: visp_video_4 {
                id = <0x4>;
                compatible = "xlnx,visp-video";

                vcap_ports24: ports {
                        #size-cells = <0x0>;
                        #address-cells = <0x1>;

                        vport41: port@0 {
                                reg = <0x0>;

                                visp_video_4_0_0: endpoint {
                                        remote-endpoint = <&visp_isp4_port40_mp>;
                                };
                        };

                        vport42: port@1 {
                                reg = <0x1>;

                                visp_video_4_0_1: endpoint {
                                        remote-endpoint = <&visp_isp4_port40_sp>;
                                };
                        };

                        vport46: port@2 {
                                reg = <0x2>;

                                visp_video_4_1_0: endpoint {
                                        remote-endpoint = <&visp_isp4_port41_mp>;
                                };
                        };

                        vport47: port@3 {
                                reg = <0x3>;

                                visp_video_4_1_1: endpoint {
                                        remote-endpoint = <&visp_isp4_port41_sp>;
                                };
                        };

                        vport411: port@4 {
                                reg = <0x4>;

                                visp_video_4_2_0: endpoint {
                                        remote-endpoint = <&visp_isp4_port42_mp>;
                                };
                        };

                        vport412: port@5 {
                                reg = <0x5>;

                                visp_video_4_2_1: endpoint {
                                        remote-endpoint = <&visp_isp4_port42_sp>;
                                };
                        };

                        vport416: port@6 {
                                reg = <0x6>;

                                visp_video_4_3_0: endpoint {
                                        remote-endpoint = <&visp_isp4_port43_mp>;
                                };
                        };

                        vport417: port@7 {
                                reg = <0x7>;

                                visp_video_4_3_1: endpoint {
                                        remote-endpoint = <&visp_isp4_port43_sp>;
                                };
                        };
                };
        };

        visp_ss_25: visp_ss@b0004800 {
                xlnx,mem_inputs = <0x0>;
                xlnx,name = "visp_ss_25";
                interrupt-names = "tile2_isp1_fusa_irq", "tile2_isp1_isp_irq";
                xlnx,rpu = <0x8>;
                xlnx,iba4_frame_rate = <0x3c>;
                isp_id = <0x5>;
                xlnx,iba4_max-width = <0xf00>;
                xlnx,iba4_data_format = <0x10>;
                xlnx,netfps = <0x3c>;
                reg = <0x0 0xb0004800 0x0 0x800>;
                xlnx,ip-name = "visp_ss";
                xlnx,num_streams = <0x1>;
                interrupt-parent = <&gic>;
                xlnx,iba4_vcid = <0x0>;
                xlnx,io_mode = "limo";
                xlnx,iba4_max-height = <0x870>;
                interrupts = <0x0 0x56 0x4 0x0 0x57 0x4>;
                compatible = "xlnx,visp-ss-limo-1.0";
                xlnx,iba4_ppc = <0x4>;

                ports25: ports {
                        #size-cells = <0x0>;
                        #address-cells = <0x1>;

                        visp_ss_250vcap_visp_ss_0: port@0 {
                                reg = <0x0>;
                        };

                        port51: port@1 {
                                reg = <0x1>;

                                visp_isp5_port50_mp: endpoint {
                                        remote-endpoint = <&visp_video_5_0_0>;
                                        type = "output";
                                };
                        };

                        port52: port@2 {
                                reg = <0x2>;

                                visp_isp5_port50_sp: endpoint {
                                        remote-endpoint = <&visp_video_5_0_1>;
                                        type = "output";
                                };
                        };
                };
        };

        visp_video_5: visp_video_5 {
                id = <0x5>;
                compatible = "xlnx,visp-video";

                vcap_ports25: ports {
                        #size-cells = <0x0>;
                        #address-cells = <0x1>;

                        vport51: port@0 {
                                reg = <0x0>;

                                visp_video_5_0_0: endpoint {
                                        remote-endpoint = <&visp_isp5_port50_mp>;
                                };
                        };

                        vport52: port@1 {
                                reg = <0x1>;

                                visp_video_5_0_1: endpoint {
                                        remote-endpoint = <&visp_isp5_port50_sp>;
                                };
                        };
                };
        };

        encoder: ale2xx@e8040000 {
                reg-names = "regs", "apb";
                xlnx,mcu-clk = <0x3b6>;
                reg = <0x0 0xe8040000 0x0 0x80000 0x0 0x8000000 0x0 0x8000000>;
                al,devicename = "al_e2xx";
                clock-names = "mcu";
                compatible = "al,ale2xx";
                interrupts = <0x2 0x6 0x2>;
                interrupt-parent = <&axi_intc_0>;
        };

        decoder: ald3xx@e8080000 {
                reg-names = "regs", "apb";
                xlnx,mcu-clk = <0x396>;
                reg = <0x0 0xe8080000 0x0 0x80000 0x0 0x0 0x0 0x8000000>;
                al,devicename = "al_d3xx";
                clock-names = "mcu";
                compatible = "al,ald3xx";
                interrupts = <0x7 0x2 0x8>;
                interrupt-parent = <&axi_intc_0>;
        };

        zyxclmm_drm {
                interrupts-extended = <&axi_intc_0 0x0 0x4>,
                 <&axi_intc_0 0x1 0x4>,
                 <&axi_intc_0 0x2 0x4>,
                 <&axi_intc_0 0x3 0x4>,
                 <&axi_intc_0 0x4 0x4>,
                 <&axi_intc_0 0x5 0x4>,
                 <&axi_intc_0 0x6 0x4>,
                 <&axi_intc_0 0x7 0x4>,
                 <&axi_intc_0 0x8 0x4>,
                 <&axi_intc_0 0x9 0x4>,
                 <&axi_intc_0 0xa 0x4>,
                 <&axi_intc_0 0xb 0x4>,
                 <&axi_intc_0 0xc 0x4>,
                 <&axi_intc_0 0xd 0x4>,
                 <&axi_intc_0 0xe 0x4>,
                 <&axi_intc_0 0xf 0x4>,
                 <&axi_intc_0 0x10 0x4>,
                 <&axi_intc_0 0x11 0x4>,
                 <&axi_intc_0 0x12 0x4>,
                 <&axi_intc_0 0x13 0x4>,
                 <&axi_intc_0 0x14 0x4>,
                 <&axi_intc_0 0x15 0x4>,
                 <&axi_intc_0 0x16 0x4>,
                 <&axi_intc_0 0x17 0x4>,
                 <&axi_intc_0 0x18 0x4>,
                 <&axi_intc_0 0x19 0x4>,
                 <&axi_intc_0 0x1a 0x4>,
                 <&axi_intc_0 0x1b 0x4>,
                 <&axi_intc_0 0x1c 0x4>,
                 <&axi_intc_0 0x1d 0x4>,
                 <&axi_intc_0 0x1e 0x4>,
                 <&axi_intc_0 0x1f 0x4>;
                compatible = "xlnx,zocl-versal";
        };
};

